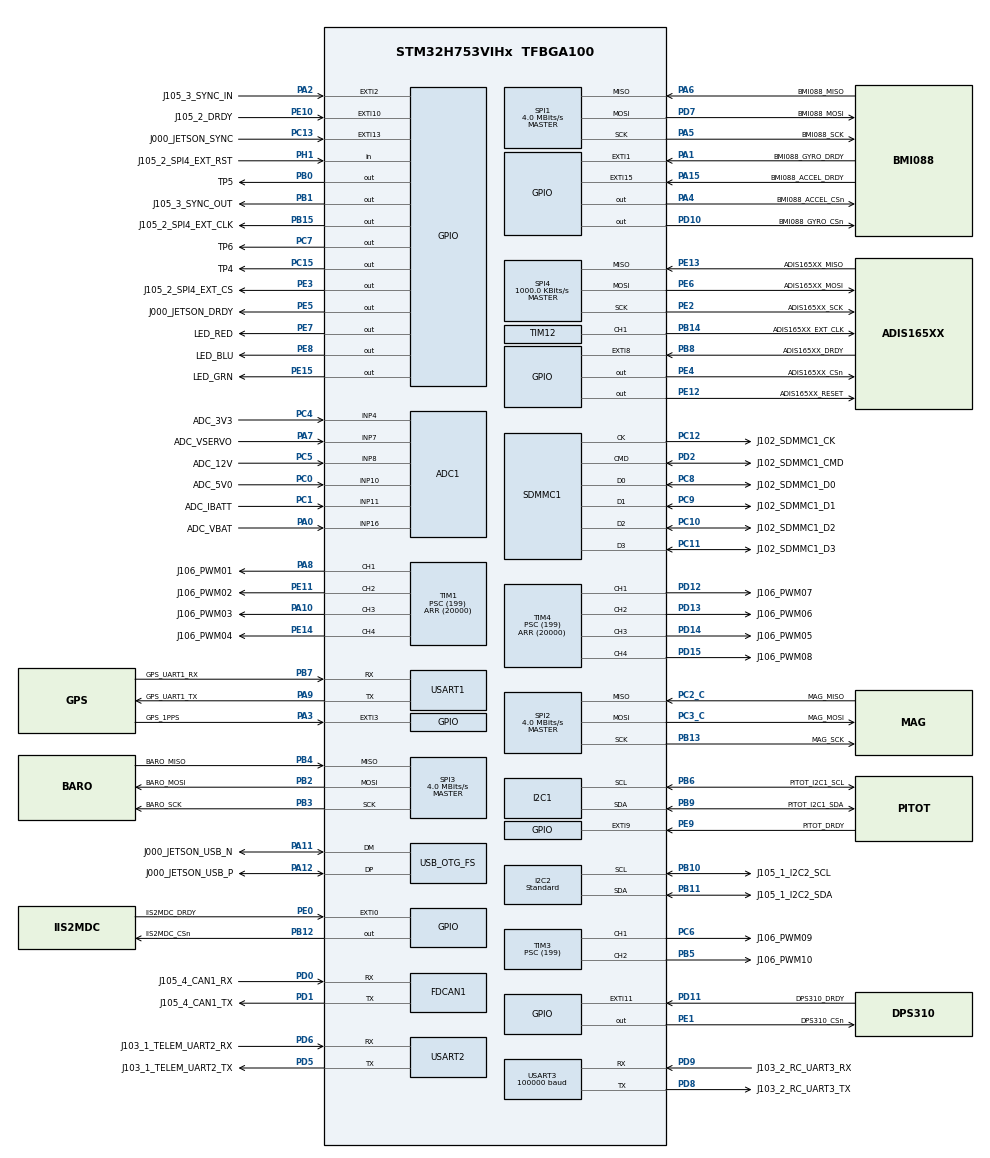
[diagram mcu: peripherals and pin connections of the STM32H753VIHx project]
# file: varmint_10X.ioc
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ADC1.Channel-0\#ChannelRegularConversion=ADC_CHANNEL_4
ADC1.Channel-1\#ChannelRegularConversion=ADC_CHANNEL_7
ADC1.Channel-2\#ChannelRegularConversion=ADC_CHANNEL_8
ADC1.Channel-3\#ChannelRegularConversion=ADC_CHANNEL_10
ADC1.Channel-4\#ChannelRegularConversion=ADC_CHANNEL_11
ADC1.Channel-5\#ChannelRegularConversion=ADC_CHANNEL_16
ADC1.ClockPrescaler=ADC_CLOCK_ASYNC_DIV32
ADC1.ClockPrescalerADC3=ADC_CLOCK_ASYNC_DIV256
ADC1.ContinuousConvMode=DISABLE
ADC1.ConversionDataManagement=ADC_CONVERSIONDATA_DMA_ONESHOT
ADC1.EOCSelection=ADC_EOC_SEQ_CONV
ADC1.EnableAnalogWatchDog2=false
ADC1.LeftBitShift=ADC_LEFTBITSHIFT_NONE
ADC1.NbrOfConversion=6
ADC1.NbrOfConversionFlag=1
ADC1.OffsetNumber-0\#ChannelRegularConversion=ADC_OFFSET_NONE
ADC1.OffsetNumber-1\#ChannelRegularConversion=ADC_OFFSET_NONE
ADC1.OffsetNumber-2\#ChannelRegularConversion=ADC_OFFSET_NONE
ADC1.OffsetNumber-3\#ChannelRegularConversion=ADC_OFFSET_NONE
ADC1.OffsetNumber-4\#ChannelRegularConversion=ADC_OFFSET_NONE
ADC1.OffsetNumber-5\#ChannelRegularConversion=ADC_OFFSET_NONE
ADC1.OffsetSignedSaturation-0\#ChannelRegularConversion=DISABLE
ADC1.OffsetSignedSaturation-1\#ChannelRegularConversion=DISABLE
ADC1.OffsetSignedSaturation-2\#ChannelRegularConversion=DISABLE
ADC1.OffsetSignedSaturation-3\#ChannelRegularConversion=DISABLE
ADC1.OffsetSignedSaturation-4\#ChannelRegularConversion=DISABLE
ADC1.OffsetSignedSaturation-5\#ChannelRegularConversion=DISABLE
ADC1.OversamplingMode=DISABLE
ADC1.Rank-0\#ChannelRegularConversion=1
ADC1.Rank-1\#ChannelRegularConversion=2
ADC1.Rank-2\#ChannelRegularConversion=3
ADC1.Rank-3\#ChannelRegularConversion=4
ADC1.Rank-4\#ChannelRegularConversion=5
ADC1.Rank-5\#ChannelRegularConversion=6
ADC1.SamplingTime-0\#ChannelRegularConversion=ADC_SAMPLETIME_810CYCLES_5
ADC1.SamplingTime-1\#ChannelRegularConversion=ADC_SAMPLETIME_810CYCLES_5
ADC1.SamplingTime-2\#ChannelRegularConversion=ADC_SAMPLETIME_810CYCLES_5
ADC1.SamplingTime-3\#ChannelRegularConversion=ADC_SAMPLETIME_810CYCLES_5
ADC1.SamplingTime-4\#ChannelRegularConversion=ADC_SAMPLETIME_810CYCLES_5
ADC1.SamplingTime-5\#ChannelRegularConversion=ADC_SAMPLETIME_810CYCLES_5
ADC1.master=1
ADC3.Channel-0\#ChannelRegularConversion=ADC_CHANNEL_TEMPSENSOR
ADC3.Channel-1\#ChannelRegularConversion=ADC_CHANNEL_VBAT
ADC3.Channel-2\#ChannelRegularConversion=ADC_CHANNEL_VREFINT
ADC3.ClockPrescaler=ADC_CLOCK_ASYNC_DIV32
ADC3.ClockPrescalerADC3=ADC_CLOCK_ASYNC_DIV256
ADC3.ContinuousConvMode=DISABLE
ADC3.ConversionDataManagement=ADC_CONVERSIONDATA_DMA_ONESHOT
ADC3.EOCSelection=ADC_EOC_SEQ_CONV
ADC3.NbrOfConversion=3
ADC3.NbrOfConversionFlag=1
ADC3.OffsetNumber-0\#ChannelRegularConversion=ADC_OFFSET_NONE
ADC3.OffsetNumber-1\#ChannelRegularConversion=ADC_OFFSET_NONE
ADC3.OffsetNumber-2\#ChannelRegularConversion=ADC_OFFSET_NONE
ADC3.OffsetSignedSaturation-0\#ChannelRegularConversion=DISABLE
ADC3.OffsetSignedSaturation-1\#ChannelRegularConversion=DISABLE
ADC3.OffsetSignedSaturation-2\#ChannelRegularConversion=DISABLE
ADC3.Rank-0\#ChannelRegularConversion=1
ADC3.Rank-1\#ChannelRegularConversion=2
ADC3.Rank-2\#ChannelRegularConversion=3
ADC3.SamplingTime-0\#ChannelRegularConversion=ADC_SAMPLETIME_810CYCLES_5
ADC3.SamplingTime-1\#ChannelRegularConversion=ADC_SAMPLETIME_810CYCLES_5
ADC3.SamplingTime-2\#ChannelRegularConversion=ADC_SAMPLETIME_810CYCLES_5
Bdma.ADC3.0.Direction=DMA_PERIPH_TO_MEMORY
Bdma.ADC3.0.EventEnable=DISABLE
Bdma.ADC3.0.Instance=BDMA_Channel0
Bdma.ADC3.0.MemDataAlignment=DMA_MDATAALIGN_WORD
Bdma.ADC3.0.MemInc=DMA_MINC_ENABLE
Bdma.ADC3.0.Mode=DMA_NORMAL
Bdma.ADC3.0.PeriphDataAlignment=DMA_PDATAALIGN_WORD
Bdma.ADC3.0.PeriphInc=DMA_PINC_DISABLE
Bdma.ADC3.0.Polarity=HAL_DMAMUX_REQ_GEN_RISING
Bdma.ADC3.0.Priority=DMA_PRIORITY_LOW
Bdma.ADC3.0.RequestNumber=1
Bdma.ADC3.0.SignalID=NONE
Bdma.ADC3.0.SyncEnable=DISABLE
Bdma.ADC3.0.SyncPolarity=HAL_DMAMUX_SYNC_NO_EVENT
Bdma.ADC3.0.SyncRequestNumber=1
Bdma.ADC3.0.SyncSignalID=NONE
Bdma.Request0=ADC3
Bdma.RequestsNb=1
CORTEX_M7.AccessPermission-Cortex_Memory_Protection_Unit_Region0_Settings=MPU_REGION_FULL_ACCESS
CORTEX_M7.AccessPermission-Cortex_Memory_Protection_Unit_Region1_Settings=MPU_REGION_FULL_ACCESS
CORTEX_M7.BaseAddress-Cortex_Memory_Protection_Unit_Region0_Settings=0x30040000
CORTEX_M7.BaseAddress-Cortex_Memory_Protection_Unit_Region1_Settings=0x38000000
CORTEX_M7.CPU_DCache=Enabled
CORTEX_M7.CPU_ICache=Enabled
CORTEX_M7.DisableExec-Cortex_Memory_Protection_Unit_Region0_Settings=MPU_INSTRUCTION_ACCESS_ENABLE
CORTEX_M7.Enable-Cortex_Memory_Protection_Unit_Region0_Settings=MPU_REGION_ENABLE
CORTEX_M7.Enable-Cortex_Memory_Protection_Unit_Region1_Settings=MPU_REGION_ENABLE
CORTEX_M7.IsCacheable-Cortex_Memory_Protection_Unit_Region0_Settings=MPU_ACCESS_CACHEABLE
CORTEX_M7.IsCacheable-Cortex_Memory_Protection_Unit_Region1_Settings=MPU_ACCESS_CACHEABLE
CORTEX_M7.IsShareable-Cortex_Memory_Protection_Unit_Region0_Settings=MPU_ACCESS_SHAREABLE
CORTEX_M7.IsShareable-Cortex_Memory_Protection_Unit_Region1_Settings=MPU_ACCESS_SHAREABLE
CORTEX_M7.MPU_Control=MPU_PRIVILEGED_DEFAULT
CORTEX_M7.Size-Cortex_Memory_Protection_Unit_Region0_Settings=MPU_REGION_SIZE_32KB
CORTEX_M7.Size-Cortex_Memory_Protection_Unit_Region1_Settings=MPU_REGION_SIZE_64KB
CORTEX_M7.SubRegionDisable-Cortex_Memory_Protection_Unit_Region0_Settings=0x00
CORTEX_M7.default_mode_Activation=0
Dma.ADC1.12.Direction=DMA_PERIPH_TO_MEMORY
Dma.ADC1.12.EventEnable=DISABLE
Dma.ADC1.12.FIFOMode=DMA_FIFOMODE_ENABLE
Dma.ADC1.12.FIFOThreshold=DMA_FIFO_THRESHOLD_FULL
Dma.ADC1.12.Instance=DMA2_Stream0
Dma.ADC1.12.MemBurst=DMA_MBURST_SINGLE
Dma.ADC1.12.MemDataAlignment=DMA_MDATAALIGN_WORD
Dma.ADC1.12.MemInc=DMA_MINC_ENABLE
Dma.ADC1.12.Mode=DMA_NORMAL
Dma.ADC1.12.PeriphBurst=DMA_PBURST_SINGLE
Dma.ADC1.12.PeriphDataAlignment=DMA_PDATAALIGN_WORD
Dma.ADC1.12.PeriphInc=DMA_PINC_DISABLE
Dma.ADC1.12.Polarity=HAL_DMAMUX_REQ_GEN_RISING
Dma.ADC1.12.Priority=DMA_PRIORITY_LOW
Dma.ADC1.12.RequestNumber=1
Dma.ADC1.12.SignalID=NONE
Dma.ADC1.12.SyncEnable=DISABLE
Dma.ADC1.12.SyncPolarity=HAL_DMAMUX_SYNC_NO_EVENT
Dma.ADC1.12.SyncRequestNumber=1
Dma.ADC1.12.SyncSignalID=NONE
Dma.I2C1_RX.10.Direction=DMA_PERIPH_TO_MEMORY
Dma.I2C1_RX.10.EventEnable=DISABLE
Dma.I2C1_RX.10.FIFOMode=DMA_FIFOMODE_ENABLE
Dma.I2C1_RX.10.FIFOThreshold=DMA_FIFO_THRESHOLD_FULL
Dma.I2C1_RX.10.Instance=DMA1_Stream0
Dma.I2C1_RX.10.MemBurst=DMA_MBURST_SINGLE
Dma.I2C1_RX.10.MemDataAlignment=DMA_MDATAALIGN_BYTE
Dma.I2C1_RX.10.MemInc=DMA_MINC_ENABLE
Dma.I2C1_RX.10.Mode=DMA_NORMAL
Dma.I2C1_RX.10.PeriphBurst=DMA_PBURST_SINGLE
Dma.I2C1_RX.10.PeriphDataAlignment=DMA_PDATAALIGN_BYTE
Dma.I2C1_RX.10.PeriphInc=DMA_PINC_DISABLE
Dma.I2C1_RX.10.Polarity=HAL_DMAMUX_REQ_GEN_RISING
Dma.I2C1_RX.10.Priority=DMA_PRIORITY_LOW
Dma.I2C1_RX.10.RequestNumber=1
Dma.I2C1_RX.10.SignalID=NONE
Dma.I2C1_RX.10.SyncEnable=DISABLE
Dma.I2C1_RX.10.SyncPolarity=HAL_DMAMUX_SYNC_NO_EVENT
Dma.I2C1_RX.10.SyncRequestNumber=1
Dma.I2C1_RX.10.SyncSignalID=NONE
Dma.I2C1_TX.11.Direction=DMA_MEMORY_TO_PERIPH
Dma.I2C1_TX.11.EventEnable=DISABLE
Dma.I2C1_TX.11.FIFOMode=DMA_FIFOMODE_ENABLE
Dma.I2C1_TX.11.FIFOThreshold=DMA_FIFO_THRESHOLD_FULL
Dma.I2C1_TX.11.Instance=DMA1_Stream1
Dma.I2C1_TX.11.MemBurst=DMA_MBURST_SINGLE
Dma.I2C1_TX.11.MemDataAlignment=DMA_MDATAALIGN_BYTE
Dma.I2C1_TX.11.MemInc=DMA_MINC_ENABLE
Dma.I2C1_TX.11.Mode=DMA_NORMAL
Dma.I2C1_TX.11.PeriphBurst=DMA_PBURST_SINGLE
Dma.I2C1_TX.11.PeriphDataAlignment=DMA_PDATAALIGN_BYTE
Dma.I2C1_TX.11.PeriphInc=DMA_PINC_DISABLE
Dma.I2C1_TX.11.Polarity=HAL_DMAMUX_REQ_GEN_RISING
Dma.I2C1_TX.11.Priority=DMA_PRIORITY_LOW
Dma.I2C1_TX.11.RequestNumber=1
Dma.I2C1_TX.11.SignalID=NONE
Dma.I2C1_TX.11.SyncEnable=DISABLE
Dma.I2C1_TX.11.SyncPolarity=HAL_DMAMUX_SYNC_NO_EVENT
Dma.I2C1_TX.11.SyncRequestNumber=1
Dma.I2C1_TX.11.SyncSignalID=NONE
Dma.I2C2_RX.14.Direction=DMA_PERIPH_TO_MEMORY
Dma.I2C2_RX.14.EventEnable=DISABLE
Dma.I2C2_RX.14.FIFOMode=DMA_FIFOMODE_ENABLE
Dma.I2C2_RX.14.FIFOThreshold=DMA_FIFO_THRESHOLD_FULL
Dma.I2C2_RX.14.Instance=DMA2_Stream6
Dma.I2C2_RX.14.MemBurst=DMA_MBURST_SINGLE
Dma.I2C2_RX.14.MemDataAlignment=DMA_MDATAALIGN_BYTE
Dma.I2C2_RX.14.MemInc=DMA_MINC_ENABLE
Dma.I2C2_RX.14.Mode=DMA_NORMAL
Dma.I2C2_RX.14.PeriphBurst=DMA_PBURST_SINGLE
Dma.I2C2_RX.14.PeriphDataAlignment=DMA_PDATAALIGN_BYTE
Dma.I2C2_RX.14.PeriphInc=DMA_PINC_DISABLE
Dma.I2C2_RX.14.Polarity=HAL_DMAMUX_REQ_GEN_RISING
Dma.I2C2_RX.14.Priority=DMA_PRIORITY_LOW
Dma.I2C2_RX.14.RequestNumber=1
Dma.I2C2_RX.14.SignalID=NONE
Dma.I2C2_RX.14.SyncEnable=DISABLE
Dma.I2C2_RX.14.SyncPolarity=HAL_DMAMUX_SYNC_NO_EVENT
Dma.I2C2_RX.14.SyncRequestNumber=1
Dma.I2C2_RX.14.SyncSignalID=NONE
Dma.I2C2_TX.15.Direction=DMA_MEMORY_TO_PERIPH
Dma.I2C2_TX.15.EventEnable=DISABLE
Dma.I2C2_TX.15.FIFOMode=DMA_FIFOMODE_ENABLE
Dma.I2C2_TX.15.FIFOThreshold=DMA_FIFO_THRESHOLD_FULL
Dma.I2C2_TX.15.Instance=DMA2_Stream7
Dma.I2C2_TX.15.MemBurst=DMA_MBURST_SINGLE
Dma.I2C2_TX.15.MemDataAlignment=DMA_MDATAALIGN_BYTE
Dma.I2C2_TX.15.MemInc=DMA_MINC_ENABLE
Dma.I2C2_TX.15.Mode=DMA_NORMAL
Dma.I2C2_TX.15.PeriphBurst=DMA_PBURST_SINGLE
Dma.I2C2_TX.15.PeriphDataAlignment=DMA_PDATAALIGN_BYTE
Dma.I2C2_TX.15.PeriphInc=DMA_PINC_DISABLE
Dma.I2C2_TX.15.Polarity=HAL_DMAMUX_REQ_GEN_RISING
Dma.I2C2_TX.15.Priority=DMA_PRIORITY_LOW
Dma.I2C2_TX.15.RequestNumber=1
Dma.I2C2_TX.15.SignalID=NONE
Dma.I2C2_TX.15.SyncEnable=DISABLE
Dma.I2C2_TX.15.SyncPolarity=HAL_DMAMUX_SYNC_NO_EVENT
Dma.I2C2_TX.15.SyncRequestNumber=1
Dma.I2C2_TX.15.SyncSignalID=NONE
Dma.Request0=SPI1_RX
Dma.Request1=SPI1_TX
Dma.Request10=I2C1_RX
Dma.Request11=I2C1_TX
Dma.Request12=ADC1
Dma.Request13=USART1_RX
Dma.Request14=I2C2_RX
Dma.Request15=I2C2_TX
Dma.Request2=SPI4_RX
Dma.Request3=SPI4_TX
Dma.Request4=SPI3_RX
Dma.Request5=SPI3_TX
Dma.Request6=SPI2_RX
Dma.Request7=SPI2_TX
Dma.Request8=USART3_RX
Dma.Request9=USART2_TX
Dma.SPI1_RX.0.Direction=DMA_PERIPH_TO_MEMORY
Dma.SPI1_RX.0.EventEnable=DISABLE
Dma.SPI1_RX.0.FIFOMode=DMA_FIFOMODE_ENABLE
Dma.SPI1_RX.0.FIFOThreshold=DMA_FIFO_THRESHOLD_FULL
Dma.SPI1_RX.0.Instance=DMA1_Stream4
Dma.SPI1_RX.0.MemBurst=DMA_MBURST_SINGLE
Dma.SPI1_RX.0.MemDataAlignment=DMA_MDATAALIGN_BYTE
Dma.SPI1_RX.0.MemInc=DMA_MINC_ENABLE
Dma.SPI1_RX.0.Mode=DMA_NORMAL
Dma.SPI1_RX.0.PeriphBurst=DMA_PBURST_SINGLE
Dma.SPI1_RX.0.PeriphDataAlignment=DMA_PDATAALIGN_BYTE
Dma.SPI1_RX.0.PeriphInc=DMA_PINC_DISABLE
Dma.SPI1_RX.0.Polarity=HAL_DMAMUX_REQ_GEN_RISING
Dma.SPI1_RX.0.Priority=DMA_PRIORITY_LOW
Dma.SPI1_RX.0.RequestNumber=1
Dma.SPI1_RX.0.SignalID=NONE
Dma.SPI1_RX.0.SyncEnable=DISABLE
Dma.SPI1_RX.0.SyncPolarity=HAL_DMAMUX_SYNC_NO_EVENT
Dma.SPI1_RX.0.SyncRequestNumber=1
Dma.SPI1_RX.0.SyncSignalID=NONE
Dma.SPI1_TX.1.Direction=DMA_MEMORY_TO_PERIPH
Dma.SPI1_TX.1.EventEnable=DISABLE
Dma.SPI1_TX.1.FIFOMode=DMA_FIFOMODE_ENABLE
Dma.SPI1_TX.1.FIFOThreshold=DMA_FIFO_THRESHOLD_FULL
Dma.SPI1_TX.1.Instance=DMA1_Stream5
Dma.SPI1_TX.1.MemBurst=DMA_MBURST_SINGLE
Dma.SPI1_TX.1.MemDataAlignment=DMA_MDATAALIGN_BYTE
Dma.SPI1_TX.1.MemInc=DMA_MINC_ENABLE
Dma.SPI1_TX.1.Mode=DMA_NORMAL
Dma.SPI1_TX.1.PeriphBurst=DMA_PBURST_SINGLE
Dma.SPI1_TX.1.PeriphDataAlignment=DMA_PDATAALIGN_BYTE
Dma.SPI1_TX.1.PeriphInc=DMA_PINC_DISABLE
Dma.SPI1_TX.1.Polarity=HAL_DMAMUX_REQ_GEN_RISING
Dma.SPI1_TX.1.Priority=DMA_PRIORITY_LOW
Dma.SPI1_TX.1.RequestNumber=1
Dma.SPI1_TX.1.SignalID=NONE
Dma.SPI1_TX.1.SyncEnable=DISABLE
Dma.SPI1_TX.1.SyncPolarity=HAL_DMAMUX_SYNC_NO_EVENT
Dma.SPI1_TX.1.SyncRequestNumber=1
Dma.SPI1_TX.1.SyncSignalID=NONE
Dma.SPI2_RX.6.Direction=DMA_PERIPH_TO_MEMORY
Dma.SPI2_RX.6.EventEnable=DISABLE
Dma.SPI2_RX.6.FIFOMode=DMA_FIFOMODE_ENABLE
Dma.SPI2_RX.6.FIFOThreshold=DMA_FIFO_THRESHOLD_FULL
Dma.SPI2_RX.6.Instance=DMA1_Stream2
Dma.SPI2_RX.6.MemBurst=DMA_MBURST_SINGLE
Dma.SPI2_RX.6.MemDataAlignment=DMA_MDATAALIGN_BYTE
Dma.SPI2_RX.6.MemInc=DMA_MINC_ENABLE
Dma.SPI2_RX.6.Mode=DMA_NORMAL
Dma.SPI2_RX.6.PeriphBurst=DMA_PBURST_SINGLE
Dma.SPI2_RX.6.PeriphDataAlignment=DMA_PDATAALIGN_BYTE
Dma.SPI2_RX.6.PeriphInc=DMA_PINC_DISABLE
Dma.SPI2_RX.6.Polarity=HAL_DMAMUX_REQ_GEN_RISING
Dma.SPI2_RX.6.Priority=DMA_PRIORITY_LOW
Dma.SPI2_RX.6.RequestNumber=1
Dma.SPI2_RX.6.SignalID=NONE
Dma.SPI2_RX.6.SyncEnable=DISABLE
Dma.SPI2_RX.6.SyncPolarity=HAL_DMAMUX_SYNC_NO_EVENT
Dma.SPI2_RX.6.SyncRequestNumber=1
Dma.SPI2_RX.6.SyncSignalID=NONE
Dma.SPI2_TX.7.Direction=DMA_MEMORY_TO_PERIPH
Dma.SPI2_TX.7.EventEnable=DISABLE
Dma.SPI2_TX.7.FIFOMode=DMA_FIFOMODE_ENABLE
Dma.SPI2_TX.7.FIFOThreshold=DMA_FIFO_THRESHOLD_FULL
Dma.SPI2_TX.7.Instance=DMA1_Stream3
Dma.SPI2_TX.7.MemBurst=DMA_MBURST_SINGLE
Dma.SPI2_TX.7.MemDataAlignment=DMA_MDATAALIGN_BYTE
Dma.SPI2_TX.7.MemInc=DMA_MINC_ENABLE
Dma.SPI2_TX.7.Mode=DMA_NORMAL
Dma.SPI2_TX.7.PeriphBurst=DMA_PBURST_SINGLE
Dma.SPI2_TX.7.PeriphDataAlignment=DMA_PDATAALIGN_BYTE
Dma.SPI2_TX.7.PeriphInc=DMA_PINC_DISABLE
Dma.SPI2_TX.7.Polarity=HAL_DMAMUX_REQ_GEN_RISING
Dma.SPI2_TX.7.Priority=DMA_PRIORITY_LOW
Dma.SPI2_TX.7.RequestNumber=1
Dma.SPI2_TX.7.SignalID=NONE
Dma.SPI2_TX.7.SyncEnable=DISABLE
Dma.SPI2_TX.7.SyncPolarity=HAL_DMAMUX_SYNC_NO_EVENT
Dma.SPI2_TX.7.SyncRequestNumber=1
Dma.SPI2_TX.7.SyncSignalID=NONE
Dma.SPI3_RX.4.Direction=DMA_PERIPH_TO_MEMORY
Dma.SPI3_RX.4.EventEnable=DISABLE
Dma.SPI3_RX.4.FIFOMode=DMA_FIFOMODE_ENABLE
Dma.SPI3_RX.4.FIFOThreshold=DMA_FIFO_THRESHOLD_FULL
Dma.SPI3_RX.4.Instance=DMA1_Stream6
Dma.SPI3_RX.4.MemBurst=DMA_MBURST_SINGLE
Dma.SPI3_RX.4.MemDataAlignment=DMA_MDATAALIGN_BYTE
Dma.SPI3_RX.4.MemInc=DMA_MINC_ENABLE
Dma.SPI3_RX.4.Mode=DMA_NORMAL
Dma.SPI3_RX.4.PeriphBurst=DMA_PBURST_SINGLE
Dma.SPI3_RX.4.PeriphDataAlignment=DMA_PDATAALIGN_BYTE
Dma.SPI3_RX.4.PeriphInc=DMA_PINC_DISABLE
Dma.SPI3_RX.4.Polarity=HAL_DMAMUX_REQ_GEN_RISING
Dma.SPI3_RX.4.Priority=DMA_PRIORITY_LOW
Dma.SPI3_RX.4.RequestNumber=1
Dma.SPI3_RX.4.SignalID=NONE
Dma.SPI3_RX.4.SyncEnable=DISABLE
Dma.SPI3_RX.4.SyncPolarity=HAL_DMAMUX_SYNC_NO_EVENT
Dma.SPI3_RX.4.SyncRequestNumber=1
Dma.SPI3_RX.4.SyncSignalID=NONE
Dma.SPI3_TX.5.Direction=DMA_MEMORY_TO_PERIPH
Dma.SPI3_TX.5.EventEnable=DISABLE
Dma.SPI3_TX.5.FIFOMode=DMA_FIFOMODE_ENABLE
Dma.SPI3_TX.5.FIFOThreshold=DMA_FIFO_THRESHOLD_FULL
Dma.SPI3_TX.5.Instance=DMA1_Stream7
Dma.SPI3_TX.5.MemBurst=DMA_MBURST_SINGLE
Dma.SPI3_TX.5.MemDataAlignment=DMA_MDATAALIGN_BYTE
Dma.SPI3_TX.5.MemInc=DMA_MINC_ENABLE
Dma.SPI3_TX.5.Mode=DMA_NORMAL
Dma.SPI3_TX.5.PeriphBurst=DMA_PBURST_SINGLE
Dma.SPI3_TX.5.PeriphDataAlignment=DMA_PDATAALIGN_BYTE
Dma.SPI3_TX.5.PeriphInc=DMA_PINC_DISABLE
Dma.SPI3_TX.5.Polarity=HAL_DMAMUX_REQ_GEN_RISING
Dma.SPI3_TX.5.Priority=DMA_PRIORITY_LOW
Dma.SPI3_TX.5.RequestNumber=1
Dma.SPI3_TX.5.SignalID=NONE
Dma.SPI3_TX.5.SyncEnable=DISABLE
Dma.SPI3_TX.5.SyncPolarity=HAL_DMAMUX_SYNC_NO_EVENT
Dma.SPI3_TX.5.SyncRequestNumber=1
Dma.SPI3_TX.5.SyncSignalID=NONE
Dma.SPI4_RX.2.Direction=DMA_PERIPH_TO_MEMORY
Dma.SPI4_RX.2.EventEnable=DISABLE
Dma.SPI4_RX.2.FIFOMode=DMA_FIFOMODE_ENABLE
Dma.SPI4_RX.2.FIFOThreshold=DMA_FIFO_THRESHOLD_FULL
Dma.SPI4_RX.2.Instance=DMA2_Stream2
Dma.SPI4_RX.2.MemBurst=DMA_MBURST_SINGLE
Dma.SPI4_RX.2.MemDataAlignment=DMA_MDATAALIGN_BYTE
Dma.SPI4_RX.2.MemInc=DMA_MINC_ENABLE
Dma.SPI4_RX.2.Mode=DMA_NORMAL
Dma.SPI4_RX.2.PeriphBurst=DMA_PBURST_SINGLE
Dma.SPI4_RX.2.PeriphDataAlignment=DMA_PDATAALIGN_BYTE
Dma.SPI4_RX.2.PeriphInc=DMA_PINC_DISABLE
Dma.SPI4_RX.2.Polarity=HAL_DMAMUX_REQ_GEN_RISING
Dma.SPI4_RX.2.Priority=DMA_PRIORITY_LOW
Dma.SPI4_RX.2.RequestNumber=1
Dma.SPI4_RX.2.SignalID=NONE
Dma.SPI4_RX.2.SyncEnable=DISABLE
Dma.SPI4_RX.2.SyncPolarity=HAL_DMAMUX_SYNC_NO_EVENT
Dma.SPI4_RX.2.SyncRequestNumber=1
Dma.SPI4_RX.2.SyncSignalID=NONE
Dma.SPI4_TX.3.Direction=DMA_MEMORY_TO_PERIPH
Dma.SPI4_TX.3.EventEnable=DISABLE
Dma.SPI4_TX.3.FIFOMode=DMA_FIFOMODE_ENABLE
Dma.SPI4_TX.3.FIFOThreshold=DMA_FIFO_THRESHOLD_FULL
Dma.SPI4_TX.3.Instance=DMA2_Stream3
Dma.SPI4_TX.3.MemBurst=DMA_MBURST_SINGLE
Dma.SPI4_TX.3.MemDataAlignment=DMA_MDATAALIGN_BYTE
Dma.SPI4_TX.3.MemInc=DMA_MINC_ENABLE
Dma.SPI4_TX.3.Mode=DMA_NORMAL
Dma.SPI4_TX.3.PeriphBurst=DMA_PBURST_SINGLE
Dma.SPI4_TX.3.PeriphDataAlignment=DMA_PDATAALIGN_BYTE
Dma.SPI4_TX.3.PeriphInc=DMA_PINC_DISABLE
Dma.SPI4_TX.3.Polarity=HAL_DMAMUX_REQ_GEN_RISING
Dma.SPI4_TX.3.Priority=DMA_PRIORITY_LOW
Dma.SPI4_TX.3.RequestNumber=1
Dma.SPI4_TX.3.SignalID=NONE
Dma.SPI4_TX.3.SyncEnable=DISABLE
Dma.SPI4_TX.3.SyncPolarity=HAL_DMAMUX_SYNC_NO_EVENT
Dma.SPI4_TX.3.SyncRequestNumber=1
Dma.SPI4_TX.3.SyncSignalID=NONE
Dma.USART1_RX.13.Direction=DMA_PERIPH_TO_MEMORY
Dma.USART1_RX.13.EventEnable=DISABLE
Dma.USART1_RX.13.FIFOMode=DMA_FIFOMODE_DISABLE
Dma.USART1_RX.13.Instance=DMA2_Stream4
Dma.USART1_RX.13.MemDataAlignment=DMA_MDATAALIGN_BYTE
Dma.USART1_RX.13.MemInc=DMA_MINC_ENABLE
Dma.USART1_RX.13.Mode=DMA_NORMAL
Dma.USART1_RX.13.PeriphDataAlignment=DMA_PDATAALIGN_BYTE
Dma.USART1_RX.13.PeriphInc=DMA_PINC_DISABLE
Dma.USART1_RX.13.Polarity=HAL_DMAMUX_REQ_GEN_RISING
Dma.USART1_RX.13.Priority=DMA_PRIORITY_LOW
Dma.USART1_RX.13.RequestNumber=1
Dma.USART1_RX.13.SignalID=NONE
Dma.USART1_RX.13.SyncEnable=DISABLE
Dma.USART1_RX.13.SyncPolarity=HAL_DMAMUX_SYNC_NO_EVENT
Dma.USART1_RX.13.SyncRequestNumber=1
Dma.USART1_RX.13.SyncSignalID=NONE
Dma.USART2_TX.9.Direction=DMA_MEMORY_TO_PERIPH
Dma.USART2_TX.9.EventEnable=DISABLE
Dma.USART2_TX.9.FIFOMode=DMA_FIFOMODE_ENABLE
Dma.USART2_TX.9.FIFOThreshold=DMA_FIFO_THRESHOLD_FULL
Dma.USART2_TX.9.Instance=DMA2_Stream5
Dma.USART2_TX.9.MemBurst=DMA_MBURST_SINGLE
Dma.USART2_TX.9.MemDataAlignment=DMA_MDATAALIGN_BYTE
Dma.USART2_TX.9.MemInc=DMA_MINC_ENABLE
Dma.USART2_TX.9.Mode=DMA_NORMAL
Dma.USART2_TX.9.PeriphBurst=DMA_PBURST_SINGLE
Dma.USART2_TX.9.PeriphDataAlignment=DMA_PDATAALIGN_BYTE
Dma.USART2_TX.9.PeriphInc=DMA_PINC_DISABLE
Dma.USART2_TX.9.Polarity=HAL_DMAMUX_REQ_GEN_RISING
Dma.USART2_TX.9.Priority=DMA_PRIORITY_LOW
Dma.USART2_TX.9.RequestNumber=1
Dma.USART2_TX.9.SignalID=NONE
Dma.USART2_TX.9.SyncEnable=DISABLE
Dma.USART2_TX.9.SyncPolarity=HAL_DMAMUX_SYNC_NO_EVENT
Dma.USART2_TX.9.SyncRequestNumber=1
Dma.USART2_TX.9.SyncSignalID=NONE
Dma.USART3_RX.8.Direction=DMA_PERIPH_TO_MEMORY
Dma.USART3_RX.8.EventEnable=DISABLE
Dma.USART3_RX.8.FIFOMode=DMA_FIFOMODE_ENABLE
Dma.USART3_RX.8.FIFOThreshold=DMA_FIFO_THRESHOLD_FULL
Dma.USART3_RX.8.Instance=DMA2_Stream1
Dma.USART3_RX.8.MemBurst=DMA_MBURST_SINGLE
Dma.USART3_RX.8.MemDataAlignment=DMA_MDATAALIGN_BYTE
Dma.USART3_RX.8.MemInc=DMA_MINC_ENABLE
Dma.USART3_RX.8.Mode=DMA_NORMAL
Dma.USART3_RX.8.PeriphBurst=DMA_PBURST_SINGLE
Dma.USART3_RX.8.PeriphDataAlignment=DMA_PDATAALIGN_BYTE
Dma.USART3_RX.8.PeriphInc=DMA_PINC_DISABLE
Dma.USART3_RX.8.Polarity=HAL_DMAMUX_REQ_GEN_RISING
Dma.USART3_RX.8.Priority=DMA_PRIORITY_LOW
Dma.USART3_RX.8.RequestNumber=1
Dma.USART3_RX.8.SignalID=NONE
Dma.USART3_RX.8.SyncEnable=DISABLE
Dma.USART3_RX.8.SyncPolarity=HAL_DMAMUX_SYNC_NO_EVENT
Dma.USART3_RX.8.SyncRequestNumber=1
Dma.USART3_RX.8.SyncSignalID=NONE
FDCAN1.CalculateBaudRateNominal=200000
FDCAN1.CalculateTimeBitNominal=5000
FDCAN1.CalculateTimeQuantumNominal=1000.0
I2C1.Timing=0x10C0ECFF
I2C2.I2C_Speed_Mode=I2C_Standard
I2C2.Timing=0x10C0ECFF
Mcu.Family=STM32H7
Mcu.Name=STM32H753VIHx
Mcu.Package=TFBGA100
NVIC.ADC3_IRQn=true\:5\:0\:true\:false\:true\:true\:true\:true
NVIC.ADC_IRQn=true\:5\:0\:true\:false\:true\:true\:true\:true
NVIC.BDMA_Channel0_IRQn=true\:5\:0\:true\:false\:true\:false\:true\:true
NVIC.DMA1_Stream0_IRQn=true\:5\:0\:true\:false\:true\:false\:true\:true
NVIC.DMA1_Stream1_IRQn=true\:5\:0\:true\:false\:true\:false\:true\:true
NVIC.DMA1_Stream2_IRQn=true\:5\:0\:true\:false\:true\:false\:true\:true
NVIC.DMA1_Stream3_IRQn=true\:5\:0\:true\:false\:true\:false\:true\:true
NVIC.DMA1_Stream4_IRQn=true\:5\:0\:true\:false\:true\:false\:true\:true
NVIC.DMA1_Stream5_IRQn=true\:5\:0\:true\:false\:true\:false\:true\:true
NVIC.DMA1_Stream6_IRQn=true\:5\:0\:true\:false\:true\:false\:true\:true
NVIC.DMA1_Stream7_IRQn=true\:5\:0\:true\:false\:true\:false\:true\:true
NVIC.DMA2_Stream0_IRQn=true\:5\:0\:true\:false\:true\:false\:true\:true
NVIC.DMA2_Stream1_IRQn=true\:5\:0\:true\:false\:true\:false\:true\:true
NVIC.DMA2_Stream2_IRQn=true\:5\:0\:true\:false\:true\:false\:true\:true
NVIC.DMA2_Stream3_IRQn=true\:5\:0\:true\:false\:true\:false\:true\:true
NVIC.DMA2_Stream4_IRQn=true\:5\:0\:true\:false\:true\:false\:true\:true
NVIC.DMA2_Stream5_IRQn=true\:5\:0\:true\:false\:true\:false\:true\:true
NVIC.DMA2_Stream6_IRQn=true\:5\:0\:true\:false\:true\:false\:true\:true
NVIC.DMA2_Stream7_IRQn=true\:5\:0\:true\:false\:true\:false\:true\:true
NVIC.EXTI0_IRQn=true\:5\:0\:true\:false\:true\:true\:true\:true
NVIC.EXTI15_10_IRQn=true\:5\:0\:true\:false\:true\:true\:true\:true
NVIC.EXTI1_IRQn=true\:5\:0\:true\:false\:true\:true\:true\:true
NVIC.EXTI2_IRQn=true\:5\:0\:true\:false\:true\:true\:true\:true
NVIC.EXTI3_IRQn=true\:5\:0\:true\:false\:true\:true\:true\:true
NVIC.EXTI9_5_IRQn=true\:5\:0\:true\:false\:true\:true\:true\:true
NVIC.I2C1_EV_IRQn=true\:5\:0\:true\:false\:true\:true\:true\:true
NVIC.I2C2_EV_IRQn=true\:5\:0\:true\:false\:true\:true\:true\:true
NVIC.OTG_FS_IRQn=true\:0\:0\:true\:false\:true\:true\:true\:true
NVIC.PriorityGroup=NVIC_PRIORITYGROUP_4
NVIC.RCC_IRQn=true\:0\:0\:true\:false\:true\:true\:false\:true
NVIC.SDMMC1_IRQn=true\:1\:0\:true\:false\:true\:true\:true\:true
NVIC.SPI1_IRQn=true\:5\:0\:true\:false\:true\:false\:true\:true
NVIC.SPI2_IRQn=true\:5\:0\:true\:false\:true\:true\:true\:true
NVIC.SPI3_IRQn=true\:5\:0\:true\:false\:true\:false\:true\:true
NVIC.SPI4_IRQn=true\:5\:0\:true\:false\:true\:false\:true\:true
NVIC.TIM17_IRQn=true\:5\:0\:true\:false\:true\:true\:true\:true
NVIC.TIM7_IRQn=true\:5\:0\:true\:false\:true\:true\:true\:true
NVIC.USART1_IRQn=true\:5\:0\:true\:false\:true\:true\:true\:true
NVIC.USART2_IRQn=true\:1\:0\:true\:false\:true\:true\:true\:true
NVIC.USART3_IRQn=true\:5\:0\:true\:false\:true\:true\:true\:true
PA0.GPIO_Label=ADC_VBAT
PA0.Mode=IN16-Single-Ended
PA0.Signal=ADC1_INP16
PA1.GPIO_Label=BMI088_GYRO_DRDY
PA1.GPIO_PuPd=GPIO_PULLDOWN
PA1.Signal=GPXTI1
PA10.GPIO_Label=J106_PWM03
PA10.Signal=S_TIM1_CH3
PA11.GPIO_Label=J000_JETSON_USB_N
PA11.Mode=Device_Only
PA11.Signal=USB_OTG_FS_DM
PA12.GPIO_Label=J000_JETSON_USB_P
PA12.Mode=Device_Only
PA12.Signal=USB_OTG_FS_DP
PA13\ (JTMS/SWDIO).GPIO_Label=J101_DEBUG_SWDIO
PA13\ (JTMS/SWDIO).Mode=Serial_Wire
PA13\ (JTMS/SWDIO).Signal=DEBUG_JTMS-SWDIO
PA14\ (JTCK/SWCLK).GPIO_Label=J101_DEBUG_SWCLK
PA14\ (JTCK/SWCLK).Mode=Serial_Wire
PA14\ (JTCK/SWCLK).Signal=DEBUG_JTCK-SWCLK
PA15\ (JTDI).GPIO_Label=BMI088_ACCEL_DRDY
PA15\ (JTDI).GPIO_PuPd=GPIO_PULLDOWN
PA15\ (JTDI).Signal=GPXTI15
PA2.GPIO_Label=J105_3_SYNC_IN
PA2.GPIO_PuPd=GPIO_PULLDOWN
PA2.Signal=GPXTI2
PA3.GPIO_Label=GPS_1PPS
PA3.GPIO_PuPd=GPIO_PULLDOWN
PA3.Signal=GPXTI3
PA4.GPIO_Label=BMI088_ACCEL_CSn
PA4.GPIO_PuPd=GPIO_NOPULL
PA4.PinState=GPIO_PIN_SET
PA4.Signal=GPIO_Output
PA5.GPIO_Label=BMI088_SCK
PA5.Mode=Full_Duplex_Master
PA5.Signal=SPI1_SCK
PA6.GPIO_Label=BMI088_MISO
PA6.Mode=Full_Duplex_Master
PA6.Signal=SPI1_MISO
PA7.GPIO_Label=ADC_VSERVO
PA7.Signal=ADCx_INP7
PA8.GPIO_Label=J106_PWM01
PA8.Signal=S_TIM1_CH1
PA9.GPIO_Label=GPS_UART1_TX
PA9.Mode=Asynchronous
PA9.Signal=USART1_TX
PB0.GPIO_Label=TP5
PB0.GPIO_PuPd=GPIO_NOPULL
PB0.Signal=GPIO_Output
PB1.GPIO_Label=J105_3_SYNC_OUT
PB1.Signal=GPIO_Output
PB10.GPIO_Label=J105_1_I2C2_SCL
PB10.Mode=I2C
PB10.Signal=I2C2_SCL
PB11.GPIO_Label=J105_1_I2C2_SDA
PB11.Mode=I2C
PB11.Signal=I2C2_SDA
PB12.GPIO_Label=IIS2MDC_CSn
PB12.GPIO_PuPd=GPIO_NOPULL
PB12.PinState=GPIO_PIN_SET
PB12.Signal=GPIO_Output
PB13.GPIO_Label=MAG_SCK
PB13.Mode=Full_Duplex_Master
PB13.PinAttribute=Free
PB13.Signal=SPI2_SCK
PB14.GPIO_Label=ADIS165XX_EXT_CLK
PB14.PinAttribute=Free
PB14.Signal=S_TIM12_CH1
PB15.GPIO_Label=J105_2_SPI4_EXT_CLK 
PB15.Signal=GPIO_Output
PB2.GPIO_Label=BARO_MOSI
PB2.Mode=Full_Duplex_Master
PB2.Signal=SPI3_MOSI
PB3\ (JTDO/TRACESWO).GPIO_Label=BARO_SCK
PB3\ (JTDO/TRACESWO).Mode=Full_Duplex_Master
PB3\ (JTDO/TRACESWO).Signal=SPI3_SCK
PB4\ (NJTRST).GPIO_Label=BARO_MISO
PB4\ (NJTRST).Mode=Full_Duplex_Master
PB4\ (NJTRST).Signal=SPI3_MISO
PB5.GPIO_Label=J106_PWM10
PB5.Signal=S_TIM3_CH2
PB6.GPIO_Label=PITOT_I2C1_SCL
PB6.GPIO_Pu=GPIO_NOPULL
PB6.Mode=I2C
PB6.PinState=GPIO_PIN_SET
PB6.Signal=I2C1_SCL
PB7.GPIO_Label=GPS_UART1_RX
PB7.Mode=Asynchronous
PB7.Signal=USART1_RX
PB7.Stacked=true
PB8.GPIO_Label=ADIS165XX_DRDY
PB8.GPIO_PuPd=GPIO_PULLDOWN
PB8.Signal=GPXTI8
PB9.GPIO_Label=PITOT_I2C1_SDA
PB9.GPIO_Mode=GPIO_MODE_AF_OD
PB9.GPIO_Pu=GPIO_NOPULL
PB9.Mode=I2C
PB9.PinState=GPIO_PIN_SET
PB9.Signal=I2C1_SDA
PC0.GPIO_Label=ADC_5V0
PC0.Signal=ADCx_INP10
PC1.GPIO_Label=ADC_IBATT
PC1.Signal=ADCx_INP11
PC10.GPIO_Label=J102_SDMMC1_D2
PC10.GPIO_PuPd=GPIO_PULLUP
PC10.Mode=SD_4_bits_Wide_bus
PC10.Signal=SDMMC1_D2
PC11.GPIO_Label=J102_SDMMC1_D3
PC11.GPIO_PuPd=GPIO_PULLUP
PC11.Mode=SD_4_bits_Wide_bus
PC11.Signal=SDMMC1_D3
PC12.GPIO_Label=J102_SDMMC1_CK
PC12.GPIO_PuPd=GPIO_PULLUP
PC12.Mode=SD_4_bits_Wide_bus
PC12.Signal=SDMMC1_CK
PC13.GPIO_Label=J000_JETSON_SYNC
PC13.GPIO_PuPd=GPIO_PULLDOWN
PC13.PinAttribute=Free
PC13.Signal=GPXTI13
PC14-OSC32_IN\ (OSC32_IN).GPIO_Label=J000_JETSON_32KHZ_CLK
PC14-OSC32_IN\ (OSC32_IN).Mode=LSE-External-Clock-Source
PC14-OSC32_IN\ (OSC32_IN).PinAttribute=Free
PC14-OSC32_IN\ (OSC32_IN).Signal=RCC_OSC32_IN
PC15-OSC32_OUT\ (OSC32_OUT).GPIO_Label=TP4
PC15-OSC32_OUT\ (OSC32_OUT).PinAttribute=Free
PC15-OSC32_OUT\ (OSC32_OUT).Signal=GPIO_Output
PC2_C.GPIO_Label=MAG_MISO
PC2_C.GPIO_PuPd=GPIO_NOPULL
PC2_C.GPIO_Speed=GPIO_SPEED_FREQ_LOW
PC2_C.Mode=Full_Duplex_Master
PC2_C.Signal=SPI2_MISO
PC3_C.GPIO_Label=MAG_MOSI
PC3_C.Mode=Full_Duplex_Master
PC3_C.Signal=SPI2_MOSI
PC4.GPIO_Label=ADC_3V3
PC4.Signal=ADCx_INP4
PC5.GPIO_Label=ADC_12V
PC5.Signal=ADCx_INP8
PC6.GPIO_Label=J106_PWM09
PC6.Signal=S_TIM3_CH1
PC7.GPIO_Label=TP6
PC7.Signal=GPIO_Output
PC8.GPIO_Label=J102_SDMMC1_D0
PC8.GPIO_PuPd=GPIO_PULLUP
PC8.Mode=SD_4_bits_Wide_bus
PC8.Signal=SDMMC1_D0
PC9.GPIO_Label=J102_SDMMC1_D1
PC9.GPIO_PuPd=GPIO_PULLUP
PC9.Mode=SD_4_bits_Wide_bus
PC9.Signal=SDMMC1_D1
PD0.GPIO_Label=J105_4_CAN1_RX
PD0.Mode=FDCAN_Activate
PD0.Signal=FDCAN1_RX
PD1.GPIO_Label=J105_4_CAN1_TX
PD1.Mode=FDCAN_Activate
PD1.Signal=FDCAN1_TX
PD10.GPIO_Label=BMI088_GYRO_CSn
PD10.GPIO_PuPd=GPIO_NOPULL
PD10.PinState=GPIO_PIN_SET
PD10.Signal=GPIO_Output
PD11.GPIO_Label=DPS310_DRDY
PD11.GPIO_PuPd=GPIO_PULLDOWN
PD11.Signal=GPXTI11
PD12.GPIO_Label=J106_PWM07
PD12.Signal=S_TIM4_CH1
PD13.GPIO_Label=J106_PWM06
PD13.Signal=S_TIM4_CH2
PD14.GPIO_Label=J106_PWM05
PD14.Signal=S_TIM4_CH3
PD15.GPIO_Label=J106_PWM08
PD15.Signal=S_TIM4_CH4
PD2.GPIO_Label=J102_SDMMC1_CMD
PD2.GPIO_PuPd=GPIO_PULLUP
PD2.Mode=SD_4_bits_Wide_bus
PD2.Signal=SDMMC1_CMD
PD3.GPIO_Label=J103_1_TELEM_UART2_CTS
PD3.Signal=USART2_CTS
PD4.GPIO_Label=J103_1_TELEM_UART2_RTS
PD4.Signal=USART2_RTS
PD5.GPIO_Label=J103_1_TELEM_UART2_TX
PD5.Mode=Asynchronous
PD5.Signal=USART2_TX
PD6.GPIO_Label=J103_1_TELEM_UART2_RX
PD6.GPIO_ModeDefaultPP=GPIO_MODE_AF_OD
PD6.GPIO_PuPd=GPIO_PULLUP
PD6.Mode=Asynchronous
PD6.Signal=USART2_RX
PD7.GPIO_Label=BMI088_MOSI
PD7.Mode=Full_Duplex_Master
PD7.Signal=SPI1_MOSI
PD8.GPIO_Label=J103_2_RC_UART3_TX
PD8.Mode=Asynchronous
PD8.Signal=USART3_TX
PD9.GPIO_Label=J103_2_RC_UART3_RX
PD9.GPIO_ModeDefaultPP=GPIO_MODE_AF_OD
PD9.GPIO_PuPd=GPIO_PULLUP
PD9.Mode=Asynchronous
PD9.Signal=USART3_RX
PE0.GPIO_Label=IIS2MDC_DRDY
PE0.GPIO_PuPd=GPIO_PULLDOWN
PE0.PinAttribute=Free
PE0.Signal=GPXTI0
PE1.GPIO_Label=DPS310_CSn
PE1.GPIO_PuPd=GPIO_NOPULL
PE1.PinAttribute=Free
PE1.PinState=GPIO_PIN_SET
PE1.Signal=GPIO_Output
PE10.GPIO_Label=J105_2_DRDY
PE10.GPIO_PuPd=GPIO_PULLDOWN
PE10.Signal=GPXTI10
PE11.GPIO_Label=J106_PWM02
PE11.Signal=S_TIM1_CH2
PE12.GPIO_Label=ADIS165XX_RESET
PE12.GPIO_PuPd=GPIO_PULLDOWN
PE12.Signal=GPIO_Output
PE13.GPIO_Label=ADIS165XX_MISO
PE13.GPIO_PuPd=GPIO_PULLUP
PE13.Mode=Full_Duplex_Master
PE13.Signal=SPI4_MISO
PE14.GPIO_Label=J106_PWM04
PE14.Signal=S_TIM1_CH4
PE15.GPIO_Label=LED_GRN
PE15.Signal=GPIO_Output
PE2.GPIO_Label=ADIS165XX_SCK
PE2.Mode=Full_Duplex_Master
PE2.Signal=SPI4_SCK
PE3.GPIO_Label=J105_2_SPI4_EXT_CS
PE3.GPIO_PuPd=GPIO_NOPULL
PE3.PinAttribute=Free
PE3.PinState=GPIO_PIN_SET
PE3.Signal=GPIO_Output
PE4.GPIO_Label=ADIS165XX_CSn
PE4.Signal=GPIO_Output
PE5.GPIO_Label=J000_JETSON_DRDY
PE5.GPIO_PuPd=GPIO_NOPULL
PE5.Signal=GPIO_Output
PE6.GPIO_Label=ADIS165XX_MOSI
PE6.Mode=Full_Duplex_Master
PE6.PinAttribute=Free
PE6.Signal=SPI4_MOSI
PE7.GPIO_Label=LED_RED
PE7.Signal=GPIO_Output
PE8.GPIO_Label=LED_BLU
PE8.Signal=GPIO_Output
PE9.GPIO_Label=PITOT_DRDY
PE9.GPIO_PuPd=GPIO_PULLDOWN
PE9.Signal=GPXTI9
PH0-OSC_IN\ (PH0).GPIO_Label=EXT_OSC
PH0-OSC_IN\ (PH0).Mode=HSE-External-Clock-Source
PH0-OSC_IN\ (PH0).PinAttribute=Free
PH0-OSC_IN\ (PH0).Signal=RCC_OSC_IN
PH1-OSC_OUT\ (PH1).GPIO_Label=J105_2_SPI4_EXT_RST
PH1-OSC_OUT\ (PH1).Signal=GPIO_Input
ProjectManager.HeapSize=0x2000
ProjectManager.StackSize=0x2000
ProjectManager.TargetToolchain=STM32CubeIDE
RCC.ADCCLockSelection=RCC_ADCCLKSOURCE_PLL3
RCC.ADCFreq_Value=64000000
RCC.APB1Freq_Value=100000000
RCC.APB2Freq_Value=100000000
RCC.APB3Freq_Value=100000000
RCC.APB4Freq_Value=100000000
RCC.CortexFreq_Value=400000000
RCC.D1PPRE=RCC_APB3_DIV2
RCC.D2PPRE1=RCC_APB1_DIV2
RCC.D2PPRE2=RCC_APB2_DIV2
RCC.D3PPRE=RCC_APB4_DIV2
RCC.DIVM1=25
RCC.DIVM2=25
RCC.DIVM3=25
RCC.DIVN1=400
RCC.DIVN2=240
RCC.DIVN3=480
RCC.DIVP2=30
RCC.DIVP3=60
RCC.DIVQ1=8
RCC.DIVQ2=30
RCC.DIVQ3=20
RCC.DIVR3=15
RCC.FDCANCLockSelection=RCC_FDCANCLKSOURCE_PLL2
RCC.FLatency-AdvancedSettings=FLASH_LATENCY_0
RCC.HCLKFreq_Value=200000000
RCC.HPRE=RCC_HCLK_DIV2
RCC.HSE_VALUE=50000000
RCC.PLL1_VCI_Range-AdvancedSettings=RCC_PLL1VCIRANGE_3
RCC.PLL1_VCO_SEL-AdvancedSettings=RCC_PLL1VCOMEDIUM
RCC.PLL2_VCI_Range-AdvancedSettings=RCC_PLL2VCIRANGE_0
RCC.PLL3_VCI_Range-AdvancedSettings=RCC_PLL3VCIRANGE_1
RCC.PLLFRACN=0
RCC.ProductRev=revV
RCC.RCC_RTC_Clock_Source_FROM_HSE=RCC_RTCCLKSOURCE_HSE_DIV8
RCC.SPI123CLockSelection=RCC_SPI123CLKSOURCE_PLL2
RCC.SYSCLKFreq_VALUE=400000000
RCC.SYSCLKSource=RCC_SYSCLKSOURCE_PLLCLK
RCC.Spi45ClockSelection=RCC_SPI45CLKSOURCE_PLL2
RCC.USBCLockSelection=RCC_USBCLKSOURCE_PLL3
RCC.USBFreq_Value=48000000
SDMMC1.ClockDiv=10
SH.ADCx_INP10.0=ADC1_INP10,IN10-Single-Ended
SH.ADCx_INP11.0=ADC1_INP11,IN11-Single-Ended
SH.ADCx_INP4.0=ADC1_INP4,IN4-Single-Ended
SH.ADCx_INP7.0=ADC1_INP7,IN7-Single-Ended
SH.ADCx_INP8.0=ADC1_INP8,IN8-Single-Ended
SH.S_TIM12_CH1.0=TIM12_CH1,PWM Generation1 CH1
SH.S_TIM1_CH1.0=TIM1_CH1,PWM Generation1 CH1
SH.S_TIM1_CH2.0=TIM1_CH2,PWM Generation2 CH2
SH.S_TIM1_CH3.0=TIM1_CH3,PWM Generation3 CH3
SH.S_TIM1_CH4.0=TIM1_CH4,PWM Generation4 CH4
SH.S_TIM3_CH1.0=TIM3_CH1,PWM Generation1 CH1
SH.S_TIM3_CH2.0=TIM3_CH2,PWM Generation2 CH2
SH.S_TIM4_CH1.0=TIM4_CH1,PWM Generation1 CH1
SH.S_TIM4_CH2.0=TIM4_CH2,PWM Generation2 CH2
SH.S_TIM4_CH3.0=TIM4_CH3,PWM Generation3 CH3
SH.S_TIM4_CH4.0=TIM4_CH4,PWM Generation4 CH4
SPI1.BaudRatePrescaler=SPI_BAUDRATEPRESCALER_4
SPI1.CLKPhase=SPI_PHASE_2EDGE
SPI1.CLKPolarity=SPI_POLARITY_HIGH
SPI1.CalculateBaudRate=4.0 MBits/s
SPI1.DataSize=SPI_DATASIZE_8BIT
SPI1.Direction=SPI_DIRECTION_2LINES
SPI1.MasterKeepIOState=SPI_MASTER_KEEP_IO_STATE_ENABLE
SPI1.Mode=SPI_MODE_MASTER
SPI1.VirtualType=VM_MASTER
SPI2.BaudRatePrescaler=SPI_BAUDRATEPRESCALER_4
SPI2.CLKPhase=SPI_PHASE_2EDGE
SPI2.CLKPolarity=SPI_POLARITY_HIGH
SPI2.CalculateBaudRate=4.0 MBits/s
SPI2.DataSize=SPI_DATASIZE_8BIT
SPI2.Direction=SPI_DIRECTION_2LINES
SPI2.MasterKeepIOState=SPI_MASTER_KEEP_IO_STATE_ENABLE
SPI2.Mode=SPI_MODE_MASTER
SPI2.VirtualType=VM_MASTER
SPI3.BaudRatePrescaler=SPI_BAUDRATEPRESCALER_4
SPI3.CLKPhase=SPI_PHASE_2EDGE
SPI3.CLKPolarity=SPI_POLARITY_HIGH
SPI3.CalculateBaudRate=4.0 MBits/s
SPI3.DataSize=SPI_DATASIZE_8BIT
SPI3.Direction=SPI_DIRECTION_2LINES
SPI3.MasterKeepIOState=SPI_MASTER_KEEP_IO_STATE_ENABLE
SPI3.Mode=SPI_MODE_MASTER
SPI3.VirtualType=VM_MASTER
SPI4.BaudRatePrescaler=SPI_BAUDRATEPRESCALER_16
SPI4.CLKPhase=SPI_PHASE_2EDGE
SPI4.CLKPolarity=SPI_POLARITY_HIGH
SPI4.CalculateBaudRate=1000.0 KBits/s
SPI4.DataSize=SPI_DATASIZE_8BIT
SPI4.Direction=SPI_DIRECTION_2LINES
SPI4.MasterInterDataIdleness=SPI_MASTER_INTERDATA_IDLENESS_01CYCLE
SPI4.MasterKeepIOState=SPI_MASTER_KEEP_IO_STATE_ENABLE
SPI4.MasterSSIdleness=SPI_MASTER_SS_IDLENESS_00CYCLE
SPI4.Mode=SPI_MODE_MASTER
SPI4.VirtualType=VM_MASTER
TIM1.AutoReloadPreload=TIM_AUTORELOAD_PRELOAD_ENABLE
TIM1.Channel-PWM\ Generation1\ CH1=TIM_CHANNEL_1
TIM1.Channel-PWM\ Generation2\ CH2=TIM_CHANNEL_2
TIM1.Channel-PWM\ Generation3\ CH3=TIM_CHANNEL_3
TIM1.Channel-PWM\ Generation4\ CH4=TIM_CHANNEL_4
TIM1.Period=(20000)
TIM1.Prescaler=(199)
TIM1.Pulse-PWM\ Generation1\ CH1=(1500)
TIM1.Pulse-PWM\ Generation2\ CH2=(1500)
TIM1.Pulse-PWM\ Generation3\ CH3=(1500)
TIM1.Pulse-PWM\ Generation4\ CH4=(1500)
TIM12.AutoReloadPreload=TIM_AUTORELOAD_PRELOAD_ENABLE
TIM12.Channel-PWM\ Generation1\ CH1=TIM_CHANNEL_1
TIM12.Channel-PWM\ Generation2\ CH2=TIM_CHANNEL_2
TIM12.Period=(ADIS165XX_TIM_PERIOD_US)
TIM12.Prescaler=199
TIM12.Pulse-PWM\ Generation1\ CH1=250
TIM17.Period=299
TIM17.Prescaler=199
TIM3.AutoReloadPreload=TIM_AUTORELOAD_PRELOAD_ENABLE
TIM3.Channel-PWM\ Generation1\ CH1=TIM_CHANNEL_1
TIM3.Channel-PWM\ Generation2\ CH2=TIM_CHANNEL_2
TIM3.Period=(20000)
TIM3.Prescaler=(199)
TIM3.Pulse-PWM\ Generation1\ CH1=(1500)
TIM3.Pulse-PWM\ Generation2\ CH2=(1500)
TIM4.AutoReloadPreload=TIM_AUTORELOAD_PRELOAD_ENABLE
TIM4.Channel-Input_Capture1_from_TI1=TIM_CHANNEL_1
TIM4.Channel-PWM\ Generation1\ CH1=TIM_CHANNEL_1
TIM4.Channel-PWM\ Generation2\ CH2=TIM_CHANNEL_2
TIM4.Channel-PWM\ Generation3\ CH3=TIM_CHANNEL_3
TIM4.Channel-PWM\ Generation4\ CH4=TIM_CHANNEL_4
TIM4.Period=(20000)
TIM4.Prescaler=(199)
TIM4.Pulse-PWM\ Generation1\ CH1=(1500)
TIM4.Pulse-PWM\ Generation2\ CH2=(1500)
TIM4.Pulse-PWM\ Generation3\ CH3=(1500)
TIM4.Pulse-PWM\ Generation4\ CH4=(1500)
TIM5.Period=0xffffffff
TIM5.Prescaler=199
TIM5.TIM_MasterOutputTrigger=TIM_TRGO_UPDATE
TIM7.AutoReloadPreload=TIM_AUTORELOAD_PRELOAD_ENABLE
TIM7.Period=(POLLING_PERIOD_US)
TIM7.Prescaler=199
USART1.VirtualMode-Asynchronous=VM_ASYNC
USART2.BaudRate=(UART2_BAUD)
USART2.FIFOMode=FIFOMODE_DISABLE
USART2.RXFIFOThreshold=RXFIFO_THRESHOLD_1EIGHTHFULL
USART2.StopBits=STOPBITS_1
USART2.TXFIFOThreshold=TXFIFO_THRESHOLD_1EIGHTHFULL
USART2.VirtualMode-Asynchronous=VM_ASYNC
USART3.BaudRate=100000
USART3.DataInvertParam=ADVFEATURE_DATAINV_DISABLE
USART3.Parity=PARITY_EVEN
USART3.RxPinLevelInvertParam=ADVFEATURE_RXINV_ENABLE
USART3.StopBits=STOPBITS_2
USART3.TxPinLevelInvertParam=ADVFEATURE_TXINV_ENABLE
USART3.VirtualMode-Asynchronous=VM_ASYNC
USART3.WordLength=WORDLENGTH_9B
USB_OTG_FS.VirtualMode=Device_Only
VP_ADC3_TempSens_Input.Mode=IN-TempSens
VP_ADC3_Vbat_Input.Mode=IN-Vbat
VP_ADC3_Vref_Input.Mode=IN-Vrefint
VP_CRC_VS_CRC.Mode=CRC_Activate
VP_RNG_VS_RNG.Mode=RNG_Activate
VP_RTC_VS_RTC_Activate.Mode=RTC_Enabled
VP_TIM17_VS_ClockSourceINT.Mode=Enable_Timer
VP_TIM5_VS_ClockSourceINT.Mode=Internal
VP_TIM7_VS_ClockSourceINT.Mode=Enable_Timer
VP_TIM8_VS_ClockSourceITR.Mode=TriggerSource_ITR3
VP_TIM8_VS_ControllerModeClock.Mode=Clock Mode
board=custom

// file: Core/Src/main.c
/* USER CODE BEGIN Header */
/**
  ******************************************************************************
  * @file           : main.c
  * @brief          : Main program body
  ******************************************************************************
  * @attention
  *
  * Copyright (c) 2023 STMicroelectronics.
  * All rights reserved.
  *
  * This software is licensed under terms that can be found in the LICENSE file
  * in the root directory of this software component.
  * If no LICENSE file comes with this software, it is provided AS-IS.
  *
  ******************************************************************************
  */
/* USER CODE END Header */
#include "main.h"

ADC_HandleTypeDef hadc1;
ADC_HandleTypeDef hadc3;
DMA_HandleTypeDef hdma_adc1;
DMA_HandleTypeDef hdma_adc3;

CRC_HandleTypeDef hcrc;

FDCAN_HandleTypeDef hfdcan1;

I2C_HandleTypeDef hi2c1;
I2C_HandleTypeDef hi2c2;
DMA_HandleTypeDef hdma_i2c1_rx;
DMA_HandleTypeDef hdma_i2c1_tx;
DMA_HandleTypeDef hdma_i2c2_rx;
DMA_HandleTypeDef hdma_i2c2_tx;

RNG_HandleTypeDef hrng;

RTC_HandleTypeDef hrtc;

SD_HandleTypeDef hsd1;

SPI_HandleTypeDef hspi1;
SPI_HandleTypeDef hspi2;
SPI_HandleTypeDef hspi3;
SPI_HandleTypeDef hspi4;
DMA_HandleTypeDef hdma_spi1_rx;
DMA_HandleTypeDef hdma_spi1_tx;
DMA_HandleTypeDef hdma_spi2_rx;
DMA_HandleTypeDef hdma_spi2_tx;
DMA_HandleTypeDef hdma_spi3_rx;
DMA_HandleTypeDef hdma_spi3_tx;
DMA_HandleTypeDef hdma_spi4_rx;
DMA_HandleTypeDef hdma_spi4_tx;

TIM_HandleTypeDef htim1;
TIM_HandleTypeDef htim3;
TIM_HandleTypeDef htim4;
TIM_HandleTypeDef htim5;
TIM_HandleTypeDef htim7;
TIM_HandleTypeDef htim8;
TIM_HandleTypeDef htim12;
TIM_HandleTypeDef htim17;

UART_HandleTypeDef huart1;
UART_HandleTypeDef huart2;
UART_HandleTypeDef huart3;
DMA_HandleTypeDef hdma_usart1_rx;
DMA_HandleTypeDef hdma_usart2_tx;
DMA_HandleTypeDef hdma_usart3_rx;

PCD_HandleTypeDef hpcd_USB_OTG_FS;

/* USER CODE BEGIN PV */
#include "CommonConfig.h"
#if 0
/* USER CODE END PV */

void SystemClock_Config(void);
void PeriphCommonClock_Config(void);
static void MPU_Config(void);

int main(void)
{

  /* MPU Configuration--------------------------------------------------------*/
  MPU_Config();
/* Enable the CPU Cache */

  /* Enable I-Cache---------------------------------------------------------*/
  SCB_EnableICache();

  /* Enable D-Cache---------------------------------------------------------*/
  SCB_EnableDCache();

  /* MCU Configuration--------------------------------------------------------*/

  /* Reset of all peripherals, Initializes the Flash interface and the Systick. */
  HAL_Init();

  /* Configure the system clock */
  SystemClock_Config();

/* Configure the peripherals common clocks */
  PeriphCommonClock_Config();

  /* Initialize all configured peripherals */
  MX_GPIO_Init();
  MX_DMA_Init();
  MX_BDMA_Init();
  MX_SPI1_Init();
  MX_SPI2_Init();
  MX_SPI3_Init();
  MX_SPI4_Init();
  MX_TIM1_Init();
  MX_TIM3_Init();
  MX_TIM4_Init();
  MX_TIM5_Init();
  MX_TIM8_Init();
  MX_TIM7_Init();
  MX_TIM12_Init();
  MX_USART2_UART_Init();
  MX_USART3_UART_Init();
  MX_ADC1_Init();
  MX_ADC3_Init();
  MX_FDCAN1_Init();
  MX_SDMMC1_SD_Init();
  MX_RTC_Init();
  MX_CRC_Init();
  MX_RNG_Init();
  MX_I2C2_Init();
  MX_USB_OTG_FS_PCD_Init();
  MX_I2C1_Init();
  MX_USART1_UART_Init();
  MX_TIM17_Init();

  /* Infinite loop */
  while (1)
  {

    /* USER CODE BEGIN 3 */
  }
#endif
  void dummy(void) {
  /* USER CODE END 3 */
}

void SystemClock_Config(void)
{
  RCC_OscInitTypeDef RCC_OscInitStruct = {0};
  RCC_ClkInitTypeDef RCC_ClkInitStruct = {0};

  /** Supply configuration update enable
  */
  HAL_PWREx_ConfigSupply(PWR_LDO_SUPPLY);

  /** Configure the main internal regulator output voltage
  */
  __HAL_PWR_VOLTAGESCALING_CONFIG(PWR_REGULATOR_VOLTAGE_SCALE1);

  while(!__HAL_PWR_GET_FLAG(PWR_FLAG_VOSRDY)) {}

  /** Initializes the RCC Oscillators according to the specified parameters
  * in the RCC_OscInitTypeDef structure.
  */
  RCC_OscInitStruct.OscillatorType = RCC_OSCILLATORTYPE_HSI48|RCC_OSCILLATORTYPE_LSI
                              |RCC_OSCILLATORTYPE_HSE;
  RCC_OscInitStruct.HSEState = RCC_HSE_BYPASS;
  RCC_OscInitStruct.LSIState = RCC_LSI_ON;
  RCC_OscInitStruct.HSI48State = RCC_HSI48_ON;
  RCC_OscInitStruct.PLL.PLLState = RCC_PLL_ON;
  RCC_OscInitStruct.PLL.PLLSource = RCC_PLLSOURCE_HSE;
  RCC_OscInitStruct.PLL.PLLM = 25;
  RCC_OscInitStruct.PLL.PLLN = 400;
  RCC_OscInitStruct.PLL.PLLP = 2;
  RCC_OscInitStruct.PLL.PLLQ = 8;
  RCC_OscInitStruct.PLL.PLLR = 2;
  RCC_OscInitStruct.PLL.PLLRGE = RCC_PLL1VCIRANGE_1;
  RCC_OscInitStruct.PLL.PLLVCOSEL = RCC_PLL1VCOWIDE;
  RCC_OscInitStruct.PLL.PLLFRACN = 0;
  if (HAL_RCC_OscConfig(&RCC_OscInitStruct) != HAL_OK)
  {
    Error_Handler();
  }

  /** Initializes the CPU, AHB and APB buses clocks
  */
  RCC_ClkInitStruct.ClockType = RCC_CLOCKTYPE_HCLK|RCC_CLOCKTYPE_SYSCLK
                              |RCC_CLOCKTYPE_PCLK1|RCC_CLOCKTYPE_PCLK2
                              |RCC_CLOCKTYPE_D3PCLK1|RCC_CLOCKTYPE_D1PCLK1;
  RCC_ClkInitStruct.SYSCLKSource = RCC_SYSCLKSOURCE_PLLCLK;
  RCC_ClkInitStruct.SYSCLKDivider = RCC_SYSCLK_DIV1;
  RCC_ClkInitStruct.AHBCLKDivider = RCC_HCLK_DIV2;
  RCC_ClkInitStruct.APB3CLKDivider = RCC_APB3_DIV2;
  RCC_ClkInitStruct.APB1CLKDivider = RCC_APB1_DIV2;
  RCC_ClkInitStruct.APB2CLKDivider = RCC_APB2_DIV2;
  RCC_ClkInitStruct.APB4CLKDivider = RCC_APB4_DIV2;

  if (HAL_RCC_ClockConfig(&RCC_ClkInitStruct, FLASH_LATENCY_2) != HAL_OK)
  {
    Error_Handler();
  }
}

void PeriphCommonClock_Config(void)
{
  RCC_PeriphCLKInitTypeDef PeriphClkInitStruct = {0};

  /** Initializes the peripherals clock
  */
  PeriphClkInitStruct.PeriphClockSelection = RCC_PERIPHCLK_USB|RCC_PERIPHCLK_ADC
                              |RCC_PERIPHCLK_SPI3|RCC_PERIPHCLK_SPI2
                              |RCC_PERIPHCLK_SPI1|RCC_PERIPHCLK_SPI4
                              |RCC_PERIPHCLK_FDCAN;
  PeriphClkInitStruct.PLL2.PLL2M = 25;
  PeriphClkInitStruct.PLL2.PLL2N = 240;
  PeriphClkInitStruct.PLL2.PLL2P = 30;
  PeriphClkInitStruct.PLL2.PLL2Q = 30;
  PeriphClkInitStruct.PLL2.PLL2R = 2;
  PeriphClkInitStruct.PLL2.PLL2RGE = RCC_PLL2VCIRANGE_1;
  PeriphClkInitStruct.PLL2.PLL2VCOSEL = RCC_PLL2VCOWIDE;
  PeriphClkInitStruct.PLL2.PLL2FRACN = 0;
  PeriphClkInitStruct.PLL3.PLL3M = 25;
  PeriphClkInitStruct.PLL3.PLL3N = 480;
  PeriphClkInitStruct.PLL3.PLL3P = 60;
  PeriphClkInitStruct.PLL3.PLL3Q = 20;
  PeriphClkInitStruct.PLL3.PLL3R = 15;
  PeriphClkInitStruct.PLL3.PLL3RGE = RCC_PLL3VCIRANGE_1;
  PeriphClkInitStruct.PLL3.PLL3VCOSEL = RCC_PLL3VCOWIDE;
  PeriphClkInitStruct.PLL3.PLL3FRACN = 0;
  PeriphClkInitStruct.Spi123ClockSelection = RCC_SPI123CLKSOURCE_PLL2;
  PeriphClkInitStruct.Spi45ClockSelection = RCC_SPI45CLKSOURCE_PLL2;
  PeriphClkInitStruct.FdcanClockSelection = RCC_FDCANCLKSOURCE_PLL2;
  PeriphClkInitStruct.UsbClockSelection = RCC_USBCLKSOURCE_PLL3;
  PeriphClkInitStruct.AdcClockSelection = RCC_ADCCLKSOURCE_PLL3;
  if (HAL_RCCEx_PeriphCLKConfig(&PeriphClkInitStruct) != HAL_OK)
  {
    Error_Handler();
  }
}

void MX_ADC1_Init(void)
{

  ADC_MultiModeTypeDef multimode = {0};
  ADC_ChannelConfTypeDef sConfig = {0};

  /** Common config
  */
  hadc1.Instance = ADC1;
  hadc1.Init.ClockPrescaler = ADC_CLOCK_ASYNC_DIV32;
  hadc1.Init.Resolution = ADC_RESOLUTION_16B;
  hadc1.Init.ScanConvMode = ADC_SCAN_ENABLE;
  hadc1.Init.EOCSelection = ADC_EOC_SEQ_CONV;
  hadc1.Init.LowPowerAutoWait = DISABLE;
  hadc1.Init.ContinuousConvMode = DISABLE;
  hadc1.Init.NbrOfConversion = 6;
  hadc1.Init.DiscontinuousConvMode = DISABLE;
  hadc1.Init.ExternalTrigConv = ADC_SOFTWARE_START;
  hadc1.Init.ExternalTrigConvEdge = ADC_EXTERNALTRIGCONVEDGE_NONE;
  hadc1.Init.ConversionDataManagement = ADC_CONVERSIONDATA_DMA_ONESHOT;
  hadc1.Init.Overrun = ADC_OVR_DATA_PRESERVED;
  hadc1.Init.LeftBitShift = ADC_LEFTBITSHIFT_NONE;
  hadc1.Init.OversamplingMode = DISABLE;
  if (HAL_ADC_Init(&hadc1) != HAL_OK)
  {
    Error_Handler();
  }

  /** Configure the ADC multi-mode
  */
  multimode.Mode = ADC_MODE_INDEPENDENT;
  if (HAL_ADCEx_MultiModeConfigChannel(&hadc1, &multimode) != HAL_OK)
  {
    Error_Handler();
  }

  /** Configure Regular Channel
  */
  sConfig.Channel = ADC_CHANNEL_4;
  sConfig.Rank = ADC_REGULAR_RANK_1;
  sConfig.SamplingTime = ADC_SAMPLETIME_810CYCLES_5;
  sConfig.SingleDiff = ADC_SINGLE_ENDED;
  sConfig.OffsetNumber = ADC_OFFSET_NONE;
  sConfig.Offset = 0;
  sConfig.OffsetSignedSaturation = DISABLE;
  if (HAL_ADC_ConfigChannel(&hadc1, &sConfig) != HAL_OK)
  {
    Error_Handler();
  }

  /** Configure Regular Channel
  */
  sConfig.Channel = ADC_CHANNEL_7;
  sConfig.Rank = ADC_REGULAR_RANK_2;
  if (HAL_ADC_ConfigChannel(&hadc1, &sConfig) != HAL_OK)
  {
    Error_Handler();
  }

  /** Configure Regular Channel
  */
  sConfig.Channel = ADC_CHANNEL_8;
  sConfig.Rank = ADC_REGULAR_RANK_3;
  if (HAL_ADC_ConfigChannel(&hadc1, &sConfig) != HAL_OK)
  {
    Error_Handler();
  }

  /** Configure Regular Channel
  */
  sConfig.Channel = ADC_CHANNEL_10;
  sConfig.Rank = ADC_REGULAR_RANK_4;
  if (HAL_ADC_ConfigChannel(&hadc1, &sConfig) != HAL_OK)
  {
    Error_Handler();
  }

  /** Configure Regular Channel
  */
  sConfig.Channel = ADC_CHANNEL_11;
  sConfig.Rank = ADC_REGULAR_RANK_5;
  if (HAL_ADC_ConfigChannel(&hadc1, &sConfig) != HAL_OK)
  {
    Error_Handler();
  }

  /** Configure Regular Channel
  */
  sConfig.Channel = ADC_CHANNEL_16;
  sConfig.Rank = ADC_REGULAR_RANK_6;
  if (HAL_ADC_ConfigChannel(&hadc1, &sConfig) != HAL_OK)
  {
    Error_Handler();
  }

}

void MX_ADC3_Init(void)
{

  ADC_ChannelConfTypeDef sConfig = {0};

  /** Common config
  */
  hadc3.Instance = ADC3;
  hadc3.Init.ClockPrescaler = ADC_CLOCK_ASYNC_DIV32;
  hadc3.Init.Resolution = ADC_RESOLUTION_16B;
  hadc3.Init.ScanConvMode = ADC_SCAN_ENABLE;
  hadc3.Init.EOCSelection = ADC_EOC_SEQ_CONV;
  hadc3.Init.LowPowerAutoWait = DISABLE;
  hadc3.Init.ContinuousConvMode = DISABLE;
  hadc3.Init.NbrOfConversion = 3;
  hadc3.Init.DiscontinuousConvMode = DISABLE;
  hadc3.Init.ExternalTrigConv = ADC_SOFTWARE_START;
  hadc3.Init.ExternalTrigConvEdge = ADC_EXTERNALTRIGCONVEDGE_NONE;
  hadc3.Init.ConversionDataManagement = ADC_CONVERSIONDATA_DMA_ONESHOT;
  hadc3.Init.Overrun = ADC_OVR_DATA_PRESERVED;
  hadc3.Init.LeftBitShift = ADC_LEFTBITSHIFT_NONE;
  hadc3.Init.OversamplingMode = DISABLE;
  if (HAL_ADC_Init(&hadc3) != HAL_OK)
  {
    Error_Handler();
  }

  /** Configure Regular Channel
  */
  sConfig.Channel = ADC_CHANNEL_TEMPSENSOR;
  sConfig.Rank = ADC_REGULAR_RANK_1;
  sConfig.SamplingTime = ADC_SAMPLETIME_810CYCLES_5;
  sConfig.SingleDiff = ADC_SINGLE_ENDED;
  sConfig.OffsetNumber = ADC_OFFSET_NONE;
  sConfig.Offset = 0;
  sConfig.OffsetSignedSaturation = DISABLE;
  if (HAL_ADC_ConfigChannel(&hadc3, &sConfig) != HAL_OK)
  {
    Error_Handler();
  }

  /** Configure Regular Channel
  */
  sConfig.Channel = ADC_CHANNEL_VBAT;
  sConfig.Rank = ADC_REGULAR_RANK_2;
  if (HAL_ADC_ConfigChannel(&hadc3, &sConfig) != HAL_OK)
  {
    Error_Handler();
  }

  /** Configure Regular Channel
  */
  sConfig.Channel = ADC_CHANNEL_VREFINT;
  sConfig.Rank = ADC_REGULAR_RANK_3;
  if (HAL_ADC_ConfigChannel(&hadc3, &sConfig) != HAL_OK)
  {
    Error_Handler();
  }

}

void MX_CRC_Init(void)
{

  hcrc.Instance = CRC;
  hcrc.Init.DefaultPolynomialUse = DEFAULT_POLYNOMIAL_ENABLE;
  hcrc.Init.DefaultInitValueUse = DEFAULT_INIT_VALUE_ENABLE;
  hcrc.Init.InputDataInversionMode = CRC_INPUTDATA_INVERSION_NONE;
  hcrc.Init.OutputDataInversionMode = CRC_OUTPUTDATA_INVERSION_DISABLE;
  hcrc.InputDataFormat = CRC_INPUTDATA_FORMAT_BYTES;
  if (HAL_CRC_Init(&hcrc) != HAL_OK)
  {
    Error_Handler();
  }

}

void MX_FDCAN1_Init(void)
{

  hfdcan1.Instance = FDCAN1;
  hfdcan1.Init.FrameFormat = FDCAN_FRAME_CLASSIC;
  hfdcan1.Init.Mode = FDCAN_MODE_NORMAL;
  hfdcan1.Init.AutoRetransmission = DISABLE;
  hfdcan1.Init.TransmitPause = DISABLE;
  hfdcan1.Init.ProtocolException = DISABLE;
  hfdcan1.Init.NominalPrescaler = 16;
  hfdcan1.Init.NominalSyncJumpWidth = 1;
  hfdcan1.Init.NominalTimeSeg1 = 2;
  hfdcan1.Init.NominalTimeSeg2 = 2;
  hfdcan1.Init.DataPrescaler = 1;
  hfdcan1.Init.DataSyncJumpWidth = 1;
  hfdcan1.Init.DataTimeSeg1 = 1;
  hfdcan1.Init.DataTimeSeg2 = 1;
  hfdcan1.Init.MessageRAMOffset = 0;
  hfdcan1.Init.StdFiltersNbr = 0;
  hfdcan1.Init.ExtFiltersNbr = 0;
  hfdcan1.Init.RxFifo0ElmtsNbr = 0;
  hfdcan1.Init.RxFifo0ElmtSize = FDCAN_DATA_BYTES_8;
  hfdcan1.Init.RxFifo1ElmtsNbr = 0;
  hfdcan1.Init.RxFifo1ElmtSize = FDCAN_DATA_BYTES_8;
  hfdcan1.Init.RxBuffersNbr = 0;
  hfdcan1.Init.RxBufferSize = FDCAN_DATA_BYTES_8;
  hfdcan1.Init.TxEventsNbr = 0;
  hfdcan1.Init.TxBuffersNbr = 0;
  hfdcan1.Init.TxFifoQueueElmtsNbr = 0;
  hfdcan1.Init.TxFifoQueueMode = FDCAN_TX_FIFO_OPERATION;
  hfdcan1.Init.TxElmtSize = FDCAN_DATA_BYTES_8;
  if (HAL_FDCAN_Init(&hfdcan1) != HAL_OK)
  {
    Error_Handler();
  }

}

void MX_I2C1_Init(void)
{

  hi2c1.Instance = I2C1;
  hi2c1.Init.Timing = 0x10C0ECFF;
  hi2c1.Init.OwnAddress1 = 0;
  hi2c1.Init.AddressingMode = I2C_ADDRESSINGMODE_7BIT;
  hi2c1.Init.DualAddressMode = I2C_DUALADDRESS_DISABLE;
  hi2c1.Init.OwnAddress2 = 0;
  hi2c1.Init.OwnAddress2Masks = I2C_OA2_NOMASK;
  hi2c1.Init.GeneralCallMode = I2C_GENERALCALL_DISABLE;
  hi2c1.Init.NoStretchMode = I2C_NOSTRETCH_DISABLE;
  if (HAL_I2C_Init(&hi2c1) != HAL_OK)
  {
    Error_Handler();
  }

  /** Configure Analogue filter
  */
  if (HAL_I2CEx_ConfigAnalogFilter(&hi2c1, I2C_ANALOGFILTER_ENABLE) != HAL_OK)
  {
    Error_Handler();
  }

  /** Configure Digital filter
  */
  if (HAL_I2CEx_ConfigDigitalFilter(&hi2c1, 0) != HAL_OK)
  {
    Error_Handler();
  }

}

void MX_I2C2_Init(void)
{

  hi2c2.Instance = I2C2;
  hi2c2.Init.Timing = 0x10C0ECFF;
  hi2c2.Init.OwnAddress1 = 0;
  hi2c2.Init.AddressingMode = I2C_ADDRESSINGMODE_7BIT;
  hi2c2.Init.DualAddressMode = I2C_DUALADDRESS_DISABLE;
  hi2c2.Init.OwnAddress2 = 0;
  hi2c2.Init.OwnAddress2Masks = I2C_OA2_NOMASK;
  hi2c2.Init.GeneralCallMode = I2C_GENERALCALL_DISABLE;
  hi2c2.Init.NoStretchMode = I2C_NOSTRETCH_DISABLE;
  if (HAL_I2C_Init(&hi2c2) != HAL_OK)
  {
    Error_Handler();
  }

  /** Configure Analogue filter
  */
  if (HAL_I2CEx_ConfigAnalogFilter(&hi2c2, I2C_ANALOGFILTER_ENABLE) != HAL_OK)
  {
    Error_Handler();
  }

  /** Configure Digital filter
  */
  if (HAL_I2CEx_ConfigDigitalFilter(&hi2c2, 0) != HAL_OK)
  {
    Error_Handler();
  }

}

void MX_RNG_Init(void)
{

  hrng.Instance = RNG;
  hrng.Init.ClockErrorDetection = RNG_CED_ENABLE;
  if (HAL_RNG_Init(&hrng) != HAL_OK)
  {
    Error_Handler();
  }

}

void MX_RTC_Init(void)
{

  /** Initialize RTC Only
  */
  hrtc.Instance = RTC;
  hrtc.Init.HourFormat = RTC_HOURFORMAT_24;
  hrtc.Init.AsynchPrediv = 127;
  hrtc.Init.SynchPrediv = 255;
  hrtc.Init.OutPut = RTC_OUTPUT_DISABLE;
  hrtc.Init.OutPutPolarity = RTC_OUTPUT_POLARITY_HIGH;
  hrtc.Init.OutPutType = RTC_OUTPUT_TYPE_OPENDRAIN;
  hrtc.Init.OutPutRemap = RTC_OUTPUT_REMAP_NONE;
  if (HAL_RTC_Init(&hrtc) != HAL_OK)
  {
    Error_Handler();
  }

}

void MX_SDMMC1_SD_Init(void)
{

  /* USER CODE BEGIN SDMMC1_Init 0 */
  hsd1.Instance = SDMMC1;
  hsd1.Init.ClockEdge = SDMMC_CLOCK_EDGE_RISING;
  hsd1.Init.ClockPowerSave = SDMMC_CLOCK_POWER_SAVE_DISABLE;
  hsd1.Init.BusWide = SDMMC_BUS_WIDE_4B;
  hsd1.Init.HardwareFlowControl = SDMMC_HARDWARE_FLOW_CONTROL_DISABLE;
  hsd1.Init.ClockDiv = 10;
  if (HAL_SD_Init(&hsd1) != HAL_OK)
  {
   // Error_Handler();
  }
  return;
  /* USER CODE END SDMMC1_Init 0 */

  hsd1.Instance = SDMMC1;
  hsd1.Init.ClockEdge = SDMMC_CLOCK_EDGE_RISING;
  hsd1.Init.ClockPowerSave = SDMMC_CLOCK_POWER_SAVE_DISABLE;
  hsd1.Init.BusWide = SDMMC_BUS_WIDE_4B;
  hsd1.Init.HardwareFlowControl = SDMMC_HARDWARE_FLOW_CONTROL_DISABLE;
  hsd1.Init.ClockDiv = 10;
  if (HAL_SD_Init(&hsd1) != HAL_OK)
  {
    Error_Handler();
  }

}

void MX_SPI1_Init(void)
{

  /* SPI1 parameter configuration*/
  hspi1.Instance = SPI1;
  hspi1.Init.Mode = SPI_MODE_MASTER;
  hspi1.Init.Direction = SPI_DIRECTION_2LINES;
  hspi1.Init.DataSize = SPI_DATASIZE_8BIT;
  hspi1.Init.CLKPolarity = SPI_POLARITY_HIGH;
  hspi1.Init.CLKPhase = SPI_PHASE_2EDGE;
  hspi1.Init.NSS = SPI_NSS_SOFT;
  hspi1.Init.BaudRatePrescaler = SPI_BAUDRATEPRESCALER_4;
  hspi1.Init.FirstBit = SPI_FIRSTBIT_MSB;
  hspi1.Init.TIMode = SPI_TIMODE_DISABLE;
  hspi1.Init.CRCCalculation = SPI_CRCCALCULATION_DISABLE;
  hspi1.Init.CRCPolynomial = 0x0;
  hspi1.Init.NSSPMode = SPI_NSS_PULSE_ENABLE;
  hspi1.Init.NSSPolarity = SPI_NSS_POLARITY_LOW;
  hspi1.Init.FifoThreshold = SPI_FIFO_THRESHOLD_01DATA;
  hspi1.Init.TxCRCInitializationPattern = SPI_CRC_INITIALIZATION_ALL_ZERO_PATTERN;
  hspi1.Init.RxCRCInitializationPattern = SPI_CRC_INITIALIZATION_ALL_ZERO_PATTERN;
  hspi1.Init.MasterSSIdleness = SPI_MASTER_SS_IDLENESS_00CYCLE;
  hspi1.Init.MasterInterDataIdleness = SPI_MASTER_INTERDATA_IDLENESS_00CYCLE;
  hspi1.Init.MasterReceiverAutoSusp = SPI_MASTER_RX_AUTOSUSP_DISABLE;
  hspi1.Init.MasterKeepIOState = SPI_MASTER_KEEP_IO_STATE_ENABLE;
  hspi1.Init.IOSwap = SPI_IO_SWAP_DISABLE;
  if (HAL_SPI_Init(&hspi1) != HAL_OK)
  {
    Error_Handler();
  }

}

void MX_SPI2_Init(void)
{

  /* SPI2 parameter configuration*/
  hspi2.Instance = SPI2;
  hspi2.Init.Mode = SPI_MODE_MASTER;
  hspi2.Init.Direction = SPI_DIRECTION_2LINES;
  hspi2.Init.DataSize = SPI_DATASIZE_8BIT;
  hspi2.Init.CLKPolarity = SPI_POLARITY_HIGH;
  hspi2.Init.CLKPhase = SPI_PHASE_2EDGE;
  hspi2.Init.NSS = SPI_NSS_SOFT;
  hspi2.Init.BaudRatePrescaler = SPI_BAUDRATEPRESCALER_4;
  hspi2.Init.FirstBit = SPI_FIRSTBIT_MSB;
  hspi2.Init.TIMode = SPI_TIMODE_DISABLE;
  hspi2.Init.CRCCalculation = SPI_CRCCALCULATION_DISABLE;
  hspi2.Init.CRCPolynomial = 0x0;
  hspi2.Init.NSSPMode = SPI_NSS_PULSE_ENABLE;
  hspi2.Init.NSSPolarity = SPI_NSS_POLARITY_LOW;
  hspi2.Init.FifoThreshold = SPI_FIFO_THRESHOLD_01DATA;
  hspi2.Init.TxCRCInitializationPattern = SPI_CRC_INITIALIZATION_ALL_ZERO_PATTERN;
  hspi2.Init.RxCRCInitializationPattern = SPI_CRC_INITIALIZATION_ALL_ZERO_PATTERN;
  hspi2.Init.MasterSSIdleness = SPI_MASTER_SS_IDLENESS_00CYCLE;
  hspi2.Init.MasterInterDataIdleness = SPI_MASTER_INTERDATA_IDLENESS_00CYCLE;
  hspi2.Init.MasterReceiverAutoSusp = SPI_MASTER_RX_AUTOSUSP_DISABLE;
  hspi2.Init.MasterKeepIOState = SPI_MASTER_KEEP_IO_STATE_ENABLE;
  hspi2.Init.IOSwap = SPI_IO_SWAP_DISABLE;
  if (HAL_SPI_Init(&hspi2) != HAL_OK)
  {
    Error_Handler();
  }

}

void MX_SPI3_Init(void)
{

  /* SPI3 parameter configuration*/
  hspi3.Instance = SPI3;
  hspi3.Init.Mode = SPI_MODE_MASTER;
  hspi3.Init.Direction = SPI_DIRECTION_2LINES;
  hspi3.Init.DataSize = SPI_DATASIZE_8BIT;
  hspi3.Init.CLKPolarity = SPI_POLARITY_HIGH;
  hspi3.Init.CLKPhase = SPI_PHASE_2EDGE;
  hspi3.Init.NSS = SPI_NSS_SOFT;
  hspi3.Init.BaudRatePrescaler = SPI_BAUDRATEPRESCALER_4;
  hspi3.Init.FirstBit = SPI_FIRSTBIT_MSB;
  hspi3.Init.TIMode = SPI_TIMODE_DISABLE;
  hspi3.Init.CRCCalculation = SPI_CRCCALCULATION_DISABLE;
  hspi3.Init.CRCPolynomial = 0x0;
  hspi3.Init.NSSPMode = SPI_NSS_PULSE_ENABLE;
  hspi3.Init.NSSPolarity = SPI_NSS_POLARITY_LOW;
  hspi3.Init.FifoThreshold = SPI_FIFO_THRESHOLD_01DATA;
  hspi3.Init.TxCRCInitializationPattern = SPI_CRC_INITIALIZATION_ALL_ZERO_PATTERN;
  hspi3.Init.RxCRCInitializationPattern = SPI_CRC_INITIALIZATION_ALL_ZERO_PATTERN;
  hspi3.Init.MasterSSIdleness = SPI_MASTER_SS_IDLENESS_00CYCLE;
  hspi3.Init.MasterInterDataIdleness = SPI_MASTER_INTERDATA_IDLENESS_00CYCLE;
  hspi3.Init.MasterReceiverAutoSusp = SPI_MASTER_RX_AUTOSUSP_DISABLE;
  hspi3.Init.MasterKeepIOState = SPI_MASTER_KEEP_IO_STATE_ENABLE;
  hspi3.Init.IOSwap = SPI_IO_SWAP_DISABLE;
  if (HAL_SPI_Init(&hspi3) != HAL_OK)
  {
    Error_Handler();
  }

}

void MX_SPI4_Init(void)
{

  /* SPI4 parameter configuration*/
  hspi4.Instance = SPI4;
  hspi4.Init.Mode = SPI_MODE_MASTER;
  hspi4.Init.Direction = SPI_DIRECTION_2LINES;
  hspi4.Init.DataSize = SPI_DATASIZE_8BIT;
  hspi4.Init.CLKPolarity = SPI_POLARITY_HIGH;
  hspi4.Init.CLKPhase = SPI_PHASE_2EDGE;
  hspi4.Init.NSS = SPI_NSS_SOFT;
  hspi4.Init.BaudRatePrescaler = SPI_BAUDRATEPRESCALER_16;
  hspi4.Init.FirstBit = SPI_FIRSTBIT_MSB;
  hspi4.Init.TIMode = SPI_TIMODE_DISABLE;
  hspi4.Init.CRCCalculation = SPI_CRCCALCULATION_DISABLE;
  hspi4.Init.CRCPolynomial = 0x0;
  hspi4.Init.NSSPMode = SPI_NSS_PULSE_ENABLE;
  hspi4.Init.NSSPolarity = SPI_NSS_POLARITY_LOW;
  hspi4.Init.FifoThreshold = SPI_FIFO_THRESHOLD_01DATA;
  hspi4.Init.TxCRCInitializationPattern = SPI_CRC_INITIALIZATION_ALL_ZERO_PATTERN;
  hspi4.Init.RxCRCInitializationPattern = SPI_CRC_INITIALIZATION_ALL_ZERO_PATTERN;
  hspi4.Init.MasterSSIdleness = SPI_MASTER_SS_IDLENESS_00CYCLE;
  hspi4.Init.MasterInterDataIdleness = SPI_MASTER_INTERDATA_IDLENESS_01CYCLE;
  hspi4.Init.MasterReceiverAutoSusp = SPI_MASTER_RX_AUTOSUSP_DISABLE;
  hspi4.Init.MasterKeepIOState = SPI_MASTER_KEEP_IO_STATE_ENABLE;
  hspi4.Init.IOSwap = SPI_IO_SWAP_DISABLE;
  if (HAL_SPI_Init(&hspi4) != HAL_OK)
  {
    Error_Handler();
  }

}

void MX_TIM1_Init(void)
{

  TIM_MasterConfigTypeDef sMasterConfig = {0};
  TIM_OC_InitTypeDef sConfigOC = {0};
  TIM_BreakDeadTimeConfigTypeDef sBreakDeadTimeConfig = {0};

  htim1.Instance = TIM1;
  htim1.Init.Prescaler = (199);
  htim1.Init.CounterMode = TIM_COUNTERMODE_UP;
  htim1.Init.Period = (20000);
  htim1.Init.ClockDivision = TIM_CLOCKDIVISION_DIV1;
  htim1.Init.RepetitionCounter = 0;
  htim1.Init.AutoReloadPreload = TIM_AUTORELOAD_PRELOAD_ENABLE;
  if (HAL_TIM_PWM_Init(&htim1) != HAL_OK)
  {
    Error_Handler();
  }
  sMasterConfig.MasterOutputTrigger = TIM_TRGO_RESET;
  sMasterConfig.MasterOutputTrigger2 = TIM_TRGO2_RESET;
  sMasterConfig.MasterSlaveMode = TIM_MASTERSLAVEMODE_DISABLE;
  if (HAL_TIMEx_MasterConfigSynchronization(&htim1, &sMasterConfig) != HAL_OK)
  {
    Error_Handler();
  }
  sConfigOC.OCMode = TIM_OCMODE_PWM1;
  sConfigOC.Pulse = (1500);
  sConfigOC.OCPolarity = TIM_OCPOLARITY_HIGH;
  sConfigOC.OCNPolarity = TIM_OCNPOLARITY_HIGH;
  sConfigOC.OCFastMode = TIM_OCFAST_DISABLE;
  sConfigOC.OCIdleState = TIM_OCIDLESTATE_RESET;
  sConfigOC.OCNIdleState = TIM_OCNIDLESTATE_RESET;
  if (HAL_TIM_PWM_ConfigChannel(&htim1, &sConfigOC, TIM_CHANNEL_1) != HAL_OK)
  {
    Error_Handler();
  }
  if (HAL_TIM_PWM_ConfigChannel(&htim1, &sConfigOC, TIM_CHANNEL_2) != HAL_OK)
  {
    Error_Handler();
  }
  if (HAL_TIM_PWM_ConfigChannel(&htim1, &sConfigOC, TIM_CHANNEL_3) != HAL_OK)
  {
    Error_Handler();
  }
  if (HAL_TIM_PWM_ConfigChannel(&htim1, &sConfigOC, TIM_CHANNEL_4) != HAL_OK)
  {
    Error_Handler();
  }
  sBreakDeadTimeConfig.OffStateRunMode = TIM_OSSR_DISABLE;
  sBreakDeadTimeConfig.OffStateIDLEMode = TIM_OSSI_DISABLE;
  sBreakDeadTimeConfig.LockLevel = TIM_LOCKLEVEL_OFF;
  sBreakDeadTimeConfig.DeadTime = 0;
  sBreakDeadTimeConfig.BreakState = TIM_BREAK_DISABLE;
  sBreakDeadTimeConfig.BreakPolarity = TIM_BREAKPOLARITY_HIGH;
  sBreakDeadTimeConfig.BreakFilter = 0;
  sBreakDeadTimeConfig.Break2State = TIM_BREAK2_DISABLE;
  sBreakDeadTimeConfig.Break2Polarity = TIM_BREAK2POLARITY_HIGH;
  sBreakDeadTimeConfig.Break2Filter = 0;
  sBreakDeadTimeConfig.AutomaticOutput = TIM_AUTOMATICOUTPUT_DISABLE;
  if (HAL_TIMEx_ConfigBreakDeadTime(&htim1, &sBreakDeadTimeConfig) != HAL_OK)
  {
    Error_Handler();
  }
  HAL_TIM_MspPostInit(&htim1);

}

void MX_TIM3_Init(void)
{

  TIM_MasterConfigTypeDef sMasterConfig = {0};
  TIM_OC_InitTypeDef sConfigOC = {0};

  htim3.Instance = TIM3;
  htim3.Init.Prescaler = (199);
  htim3.Init.CounterMode = TIM_COUNTERMODE_UP;
  htim3.Init.Period = (20000);
  htim3.Init.ClockDivision = TIM_CLOCKDIVISION_DIV1;
  htim3.Init.AutoReloadPreload = TIM_AUTORELOAD_PRELOAD_ENABLE;
  if (HAL_TIM_PWM_Init(&htim3) != HAL_OK)
  {
    Error_Handler();
  }
  sMasterConfig.MasterOutputTrigger = TIM_TRGO_RESET;
  sMasterConfig.MasterSlaveMode = TIM_MASTERSLAVEMODE_DISABLE;
  if (HAL_TIMEx_MasterConfigSynchronization(&htim3, &sMasterConfig) != HAL_OK)
  {
    Error_Handler();
  }
  sConfigOC.OCMode = TIM_OCMODE_PWM1;
  sConfigOC.Pulse = (1500);
  sConfigOC.OCPolarity = TIM_OCPOLARITY_HIGH;
  sConfigOC.OCFastMode = TIM_OCFAST_DISABLE;
  if (HAL_TIM_PWM_ConfigChannel(&htim3, &sConfigOC, TIM_CHANNEL_1) != HAL_OK)
  {
    Error_Handler();
  }
  if (HAL_TIM_PWM_ConfigChannel(&htim3, &sConfigOC, TIM_CHANNEL_2) != HAL_OK)
  {
    Error_Handler();
  }
  HAL_TIM_MspPostInit(&htim3);

}

void MX_TIM4_Init(void)
{

  TIM_MasterConfigTypeDef sMasterConfig = {0};
  TIM_OC_InitTypeDef sConfigOC = {0};

  htim4.Instance = TIM4;
  htim4.Init.Prescaler = (199);
  htim4.Init.CounterMode = TIM_COUNTERMODE_UP;
  htim4.Init.Period = (20000);
  htim4.Init.ClockDivision = TIM_CLOCKDIVISION_DIV1;
  htim4.Init.AutoReloadPreload = TIM_AUTORELOAD_PRELOAD_ENABLE;
  if (HAL_TIM_PWM_Init(&htim4) != HAL_OK)
  {
    Error_Handler();
  }
  sMasterConfig.MasterOutputTrigger = TIM_TRGO_RESET;
  sMasterConfig.MasterSlaveMode = TIM_MASTERSLAVEMODE_DISABLE;
  if (HAL_TIMEx_MasterConfigSynchronization(&htim4, &sMasterConfig) != HAL_OK)
  {
    Error_Handler();
  }
  sConfigOC.OCMode = TIM_OCMODE_PWM1;
  sConfigOC.Pulse = (1500);
  sConfigOC.OCPolarity = TIM_OCPOLARITY_HIGH;
  sConfigOC.OCFastMode = TIM_OCFAST_DISABLE;
  if (HAL_TIM_PWM_ConfigChannel(&htim4, &sConfigOC, TIM_CHANNEL_1) != HAL_OK)
  {
    Error_Handler();
  }
  if (HAL_TIM_PWM_ConfigChannel(&htim4, &sConfigOC, TIM_CHANNEL_2) != HAL_OK)
  {
    Error_Handler();
  }
  if (HAL_TIM_PWM_ConfigChannel(&htim4, &sConfigOC, TIM_CHANNEL_3) != HAL_OK)
  {
    Error_Handler();
  }
  if (HAL_TIM_PWM_ConfigChannel(&htim4, &sConfigOC, TIM_CHANNEL_4) != HAL_OK)
  {
    Error_Handler();
  }
  HAL_TIM_MspPostInit(&htim4);

}

void MX_TIM5_Init(void)
{

  TIM_ClockConfigTypeDef sClockSourceConfig = {0};
  TIM_MasterConfigTypeDef sMasterConfig = {0};

  htim5.Instance = TIM5;
  htim5.Init.Prescaler = 199;
  htim5.Init.CounterMode = TIM_COUNTERMODE_UP;
  htim5.Init.Period = 0xffffffff;
  htim5.Init.ClockDivision = TIM_CLOCKDIVISION_DIV1;
  htim5.Init.AutoReloadPreload = TIM_AUTORELOAD_PRELOAD_DISABLE;
  if (HAL_TIM_Base_Init(&htim5) != HAL_OK)
  {
    Error_Handler();
  }
  sClockSourceConfig.ClockSource = TIM_CLOCKSOURCE_INTERNAL;
  if (HAL_TIM_ConfigClockSource(&htim5, &sClockSourceConfig) != HAL_OK)
  {
    Error_Handler();
  }
  sMasterConfig.MasterOutputTrigger = TIM_TRGO_UPDATE;
  sMasterConfig.MasterSlaveMode = TIM_MASTERSLAVEMODE_DISABLE;
  if (HAL_TIMEx_MasterConfigSynchronization(&htim5, &sMasterConfig) != HAL_OK)
  {
    Error_Handler();
  }

}

void MX_TIM7_Init(void)
{

  /* USER CODE BEGIN TIM7_Init 0 */
#define POLLING_PERIOD_US         (100) // 100us, 10kHz
//#define POLLING_FREQ_HZ          	(1000000/POLLING_PERIOD_US) // 10000 Hz
  /* USER CODE END TIM7_Init 0 */

  TIM_MasterConfigTypeDef sMasterConfig = {0};

  htim7.Instance = TIM7;
  htim7.Init.Prescaler = 199;
  htim7.Init.CounterMode = TIM_COUNTERMODE_UP;
  htim7.Init.Period = (POLLING_PERIOD_US);
  htim7.Init.AutoReloadPreload = TIM_AUTORELOAD_PRELOAD_ENABLE;
  if (HAL_TIM_Base_Init(&htim7) != HAL_OK)
  {
    Error_Handler();
  }
  sMasterConfig.MasterOutputTrigger = TIM_TRGO_RESET;
  sMasterConfig.MasterSlaveMode = TIM_MASTERSLAVEMODE_DISABLE;
  if (HAL_TIMEx_MasterConfigSynchronization(&htim7, &sMasterConfig) != HAL_OK)
  {
    Error_Handler();
  }

}

void MX_TIM8_Init(void)
{

  TIM_SlaveConfigTypeDef sSlaveConfig = {0};
  TIM_MasterConfigTypeDef sMasterConfig = {0};

  htim8.Instance = TIM8;
  htim8.Init.Prescaler = 0;
  htim8.Init.CounterMode = TIM_COUNTERMODE_UP;
  htim8.Init.Period = 65535;
  htim8.Init.ClockDivision = TIM_CLOCKDIVISION_DIV1;
  htim8.Init.RepetitionCounter = 0;
  htim8.Init.AutoReloadPreload = TIM_AUTORELOAD_PRELOAD_DISABLE;
  if (HAL_TIM_Base_Init(&htim8) != HAL_OK)
  {
    Error_Handler();
  }
  sSlaveConfig.SlaveMode = TIM_SLAVEMODE_EXTERNAL1;
  sSlaveConfig.InputTrigger = TIM_TS_ITR3;
  if (HAL_TIM_SlaveConfigSynchro(&htim8, &sSlaveConfig) != HAL_OK)
  {
    Error_Handler();
  }
  sMasterConfig.MasterOutputTrigger = TIM_TRGO_RESET;
  sMasterConfig.MasterOutputTrigger2 = TIM_TRGO2_RESET;
  sMasterConfig.MasterSlaveMode = TIM_MASTERSLAVEMODE_DISABLE;
  if (HAL_TIMEx_MasterConfigSynchronization(&htim8, &sMasterConfig) != HAL_OK)
  {
    Error_Handler();
  }

}

void MX_TIM12_Init(void)
{

  /* USER CODE BEGIN TIM12_Init 0 */
  #define ADIS165XX_TIM_PERIOD_US (500)
  /* USER CODE END TIM12_Init 0 */

  TIM_MasterConfigTypeDef sMasterConfig = {0};
  TIM_OC_InitTypeDef sConfigOC = {0};

  htim12.Instance = TIM12;
  htim12.Init.Prescaler = 199;
  htim12.Init.CounterMode = TIM_COUNTERMODE_UP;
  htim12.Init.Period = (ADIS165XX_TIM_PERIOD_US);
  htim12.Init.ClockDivision = TIM_CLOCKDIVISION_DIV1;
  htim12.Init.AutoReloadPreload = TIM_AUTORELOAD_PRELOAD_ENABLE;
  if (HAL_TIM_PWM_Init(&htim12) != HAL_OK)
  {
    Error_Handler();
  }
  sMasterConfig.MasterOutputTrigger = TIM_TRGO_RESET;
  sMasterConfig.MasterSlaveMode = TIM_MASTERSLAVEMODE_DISABLE;
  if (HAL_TIMEx_MasterConfigSynchronization(&htim12, &sMasterConfig) != HAL_OK)
  {
    Error_Handler();
  }
  sConfigOC.OCMode = TIM_OCMODE_PWM1;
  sConfigOC.Pulse = 250;
  sConfigOC.OCPolarity = TIM_OCPOLARITY_HIGH;
  sConfigOC.OCFastMode = TIM_OCFAST_DISABLE;
  if (HAL_TIM_PWM_ConfigChannel(&htim12, &sConfigOC, TIM_CHANNEL_1) != HAL_OK)
  {
    Error_Handler();
  }
  HAL_TIM_MspPostInit(&htim12);

}

void MX_TIM17_Init(void)
{

  htim17.Instance = TIM17;
  htim17.Init.Prescaler = 199;
  htim17.Init.CounterMode = TIM_COUNTERMODE_UP;
  htim17.Init.Period = 299;
  htim17.Init.ClockDivision = TIM_CLOCKDIVISION_DIV1;
  htim17.Init.RepetitionCounter = 0;
  htim17.Init.AutoReloadPreload = TIM_AUTORELOAD_PRELOAD_DISABLE;
  if (HAL_TIM_Base_Init(&htim17) != HAL_OK)
  {
    Error_Handler();
  }

}

void MX_USART1_UART_Init(void)
{

  huart1.Instance = USART1;
  huart1.Init.BaudRate = 115200;
  huart1.Init.WordLength = UART_WORDLENGTH_8B;
  huart1.Init.StopBits = UART_STOPBITS_1;
  huart1.Init.Parity = UART_PARITY_NONE;
  huart1.Init.Mode = UART_MODE_TX_RX;
  huart1.Init.HwFlowCtl = UART_HWCONTROL_NONE;
  huart1.Init.OverSampling = UART_OVERSAMPLING_16;
  huart1.Init.OneBitSampling = UART_ONE_BIT_SAMPLE_DISABLE;
  huart1.Init.ClockPrescaler = UART_PRESCALER_DIV1;
  huart1.AdvancedInit.AdvFeatureInit = UART_ADVFEATURE_NO_INIT;
  if (HAL_UART_Init(&huart1) != HAL_OK)
  {
    Error_Handler();
  }
  if (HAL_UARTEx_SetTxFifoThreshold(&huart1, UART_TXFIFO_THRESHOLD_1_8) != HAL_OK)
  {
    Error_Handler();
  }
  if (HAL_UARTEx_SetRxFifoThreshold(&huart1, UART_RXFIFO_THRESHOLD_1_8) != HAL_OK)
  {
    Error_Handler();
  }
  if (HAL_UARTEx_DisableFifoMode(&huart1) != HAL_OK)
  {
    Error_Handler();
  }

}

void MX_USART2_UART_Init(void)
{

  /* USER CODE BEGIN USART2_Init 0 */
#define UART2_BAUD        				(921600)
  /* USER CODE END USART2_Init 0 */

  huart2.Instance = USART2;
  huart2.Init.BaudRate = (UART2_BAUD);
  huart2.Init.WordLength = UART_WORDLENGTH_8B;
  huart2.Init.StopBits = UART_STOPBITS_1;
  huart2.Init.Parity = UART_PARITY_NONE;
  huart2.Init.Mode = UART_MODE_TX_RX;
  huart2.Init.HwFlowCtl = UART_HWCONTROL_NONE;
  huart2.Init.OverSampling = UART_OVERSAMPLING_16;
  huart2.Init.OneBitSampling = UART_ONE_BIT_SAMPLE_DISABLE;
  huart2.Init.ClockPrescaler = UART_PRESCALER_DIV1;
  huart2.AdvancedInit.AdvFeatureInit = UART_ADVFEATURE_NO_INIT;
  if (HAL_UART_Init(&huart2) != HAL_OK)
  {
    Error_Handler();
  }
  if (HAL_UARTEx_SetTxFifoThreshold(&huart2, UART_TXFIFO_THRESHOLD_1_8) != HAL_OK)
  {
    Error_Handler();
  }
  if (HAL_UARTEx_SetRxFifoThreshold(&huart2, UART_RXFIFO_THRESHOLD_1_8) != HAL_OK)
  {
    Error_Handler();
  }
  if (HAL_UARTEx_DisableFifoMode(&huart2) != HAL_OK)
  {
    Error_Handler();
  }

}

void MX_USART3_UART_Init(void)
{

  huart3.Instance = USART3;
  huart3.Init.BaudRate = 100000;
  huart3.Init.WordLength = UART_WORDLENGTH_9B;
  huart3.Init.StopBits = UART_STOPBITS_2;
  huart3.Init.Parity = UART_PARITY_EVEN;
  huart3.Init.Mode = UART_MODE_TX_RX;
  huart3.Init.HwFlowCtl = UART_HWCONTROL_NONE;
  huart3.Init.OverSampling = UART_OVERSAMPLING_16;
  huart3.Init.OneBitSampling = UART_ONE_BIT_SAMPLE_DISABLE;
  huart3.Init.ClockPrescaler = UART_PRESCALER_DIV1;
  huart3.AdvancedInit.AdvFeatureInit = UART_ADVFEATURE_TXINVERT_INIT|UART_ADVFEATURE_RXINVERT_INIT;
  huart3.AdvancedInit.TxPinLevelInvert = UART_ADVFEATURE_TXINV_ENABLE;
  huart3.AdvancedInit.RxPinLevelInvert = UART_ADVFEATURE_RXINV_ENABLE;
  if (HAL_UART_Init(&huart3) != HAL_OK)
  {
    Error_Handler();
  }
  if (HAL_UARTEx_SetTxFifoThreshold(&huart3, UART_TXFIFO_THRESHOLD_1_8) != HAL_OK)
  {
    Error_Handler();
  }
  if (HAL_UARTEx_SetRxFifoThreshold(&huart3, UART_RXFIFO_THRESHOLD_1_8) != HAL_OK)
  {
    Error_Handler();
  }
  if (HAL_UARTEx_DisableFifoMode(&huart3) != HAL_OK)
  {
    Error_Handler();
  }

}

void MX_USB_OTG_FS_PCD_Init(void)
{

  hpcd_USB_OTG_FS.Instance = USB_OTG_FS;
  hpcd_USB_OTG_FS.Init.dev_endpoints = 9;
  hpcd_USB_OTG_FS.Init.speed = PCD_SPEED_FULL;
  hpcd_USB_OTG_FS.Init.dma_enable = DISABLE;
  hpcd_USB_OTG_FS.Init.phy_itface = PCD_PHY_EMBEDDED;
  hpcd_USB_OTG_FS.Init.Sof_enable = DISABLE;
  hpcd_USB_OTG_FS.Init.low_power_enable = DISABLE;
  hpcd_USB_OTG_FS.Init.lpm_enable = DISABLE;
  hpcd_USB_OTG_FS.Init.battery_charging_enable = DISABLE;
  hpcd_USB_OTG_FS.Init.vbus_sensing_enable = DISABLE;
  hpcd_USB_OTG_FS.Init.use_dedicated_ep1 = DISABLE;
  if (HAL_PCD_Init(&hpcd_USB_OTG_FS) != HAL_OK)
  {
    Error_Handler();
  }

}

void MX_BDMA_Init(void)
{

  /* DMA controller clock enable */
  __HAL_RCC_BDMA_CLK_ENABLE();

  /* DMA interrupt init */
  /* BDMA_Channel0_IRQn interrupt configuration */
  HAL_NVIC_SetPriority(BDMA_Channel0_IRQn, 5, 0);
  HAL_NVIC_EnableIRQ(BDMA_Channel0_IRQn);

}

void MX_DMA_Init(void)
{

  /* DMA controller clock enable */
  __HAL_RCC_DMA1_CLK_ENABLE();
  __HAL_RCC_DMA2_CLK_ENABLE();

  /* DMA interrupt init */
  /* DMA1_Stream0_IRQn interrupt configuration */
  HAL_NVIC_SetPriority(DMA1_Stream0_IRQn, 5, 0);
  HAL_NVIC_EnableIRQ(DMA1_Stream0_IRQn);
  /* DMA1_Stream1_IRQn interrupt configuration */
  HAL_NVIC_SetPriority(DMA1_Stream1_IRQn, 5, 0);
  HAL_NVIC_EnableIRQ(DMA1_Stream1_IRQn);
  /* DMA1_Stream2_IRQn interrupt configuration */
  HAL_NVIC_SetPriority(DMA1_Stream2_IRQn, 5, 0);
  HAL_NVIC_EnableIRQ(DMA1_Stream2_IRQn);
  /* DMA1_Stream3_IRQn interrupt configuration */
  HAL_NVIC_SetPriority(DMA1_Stream3_IRQn, 5, 0);
  HAL_NVIC_EnableIRQ(DMA1_Stream3_IRQn);
  /* DMA1_Stream4_IRQn interrupt configuration */
  HAL_NVIC_SetPriority(DMA1_Stream4_IRQn, 5, 0);
  HAL_NVIC_EnableIRQ(DMA1_Stream4_IRQn);
  /* DMA1_Stream5_IRQn interrupt configuration */
  HAL_NVIC_SetPriority(DMA1_Stream5_IRQn, 5, 0);
  HAL_NVIC_EnableIRQ(DMA1_Stream5_IRQn);
  /* DMA1_Stream6_IRQn interrupt configuration */
  HAL_NVIC_SetPriority(DMA1_Stream6_IRQn, 5, 0);
  HAL_NVIC_EnableIRQ(DMA1_Stream6_IRQn);
  /* DMA1_Stream7_IRQn interrupt configuration */
  HAL_NVIC_SetPriority(DMA1_Stream7_IRQn, 5, 0);
  HAL_NVIC_EnableIRQ(DMA1_Stream7_IRQn);
  /* DMA2_Stream0_IRQn interrupt configuration */
  HAL_NVIC_SetPriority(DMA2_Stream0_IRQn, 5, 0);
  HAL_NVIC_EnableIRQ(DMA2_Stream0_IRQn);
  /* DMA2_Stream1_IRQn interrupt configuration */
  HAL_NVIC_SetPriority(DMA2_Stream1_IRQn, 5, 0);
  HAL_NVIC_EnableIRQ(DMA2_Stream1_IRQn);
  /* DMA2_Stream2_IRQn interrupt configuration */
  HAL_NVIC_SetPriority(DMA2_Stream2_IRQn, 5, 0);
  HAL_NVIC_EnableIRQ(DMA2_Stream2_IRQn);
  /* DMA2_Stream3_IRQn interrupt configuration */
  HAL_NVIC_SetPriority(DMA2_Stream3_IRQn, 5, 0);
  HAL_NVIC_EnableIRQ(DMA2_Stream3_IRQn);
  /* DMA2_Stream4_IRQn interrupt configuration */
  HAL_NVIC_SetPriority(DMA2_Stream4_IRQn, 5, 0);
  HAL_NVIC_EnableIRQ(DMA2_Stream4_IRQn);
  /* DMA2_Stream5_IRQn interrupt configuration */
  HAL_NVIC_SetPriority(DMA2_Stream5_IRQn, 5, 0);
  HAL_NVIC_EnableIRQ(DMA2_Stream5_IRQn);
  /* DMA2_Stream6_IRQn interrupt configuration */
  HAL_NVIC_SetPriority(DMA2_Stream6_IRQn, 5, 0);
  HAL_NVIC_EnableIRQ(DMA2_Stream6_IRQn);
  /* DMA2_Stream7_IRQn interrupt configuration */
  HAL_NVIC_SetPriority(DMA2_Stream7_IRQn, 5, 0);
  HAL_NVIC_EnableIRQ(DMA2_Stream7_IRQn);

}

void MX_GPIO_Init(void)
{
  GPIO_InitTypeDef GPIO_InitStruct = {0};

  /* GPIO Ports Clock Enable */
  __HAL_RCC_GPIOC_CLK_ENABLE();
  __HAL_RCC_GPIOE_CLK_ENABLE();
  __HAL_RCC_GPIOB_CLK_ENABLE();
  __HAL_RCC_GPIOA_CLK_ENABLE();
  __HAL_RCC_GPIOD_CLK_ENABLE();
  __HAL_RCC_GPIOH_CLK_ENABLE();

  /*Configure GPIO pin Output Level */
  HAL_GPIO_WritePin(GPIOC, TP4_Pin|TP6_Pin, GPIO_PIN_RESET);

  /*Configure GPIO pin Output Level */
  HAL_GPIO_WritePin(GPIOE, J105_2_SPI4_EXT_CS_Pin|DPS310_CSn_Pin, GPIO_PIN_SET);

  /*Configure GPIO pin Output Level */
  HAL_GPIO_WritePin(GPIOE, ADIS165XX_CSn_Pin|J000_JETSON_DRDY_Pin|LED_RED_Pin|LED_GRN_Pin
                          |LED_BLU_Pin|ADIS165XX_RESET_Pin, GPIO_PIN_RESET);

  /*Configure GPIO pin Output Level */
  HAL_GPIO_WritePin(BMI088_ACCEL_CSn_GPIO_Port, BMI088_ACCEL_CSn_Pin, GPIO_PIN_SET);

  /*Configure GPIO pin Output Level */
  HAL_GPIO_WritePin(GPIOB, J105_2_SPI4_EXT_CLK_Pin|TP5_Pin|J105_3_SYNC_OUT_Pin, GPIO_PIN_RESET);

  /*Configure GPIO pin Output Level */
  HAL_GPIO_WritePin(BMI088_GYRO_CSn_GPIO_Port, BMI088_GYRO_CSn_Pin, GPIO_PIN_SET);

  /*Configure GPIO pin Output Level */
  HAL_GPIO_WritePin(IIS2MDC_CSn_GPIO_Port, IIS2MDC_CSn_Pin, GPIO_PIN_SET);

  /*Configure GPIO pin : J000_JETSON_SYNC_Pin */
  GPIO_InitStruct.Pin = J000_JETSON_SYNC_Pin;
  GPIO_InitStruct.Mode = GPIO_MODE_IT_RISING;
  GPIO_InitStruct.Pull = GPIO_PULLDOWN;
  HAL_GPIO_Init(J000_JETSON_SYNC_GPIO_Port, &GPIO_InitStruct);

  /*Configure GPIO pins : BMI088_ACCEL_DRDY_Pin BMI088_GYRO_DRDY_Pin J105_3_SYNC_IN_Pin GPS_1PPS_Pin */
  GPIO_InitStruct.Pin = BMI088_ACCEL_DRDY_Pin|BMI088_GYRO_DRDY_Pin|J105_3_SYNC_IN_Pin|GPS_1PPS_Pin;
  GPIO_InitStruct.Mode = GPIO_MODE_IT_RISING;
  GPIO_InitStruct.Pull = GPIO_PULLDOWN;
  HAL_GPIO_Init(GPIOA, &GPIO_InitStruct);

  /*Configure GPIO pins : TP4_Pin TP6_Pin */
  GPIO_InitStruct.Pin = TP4_Pin|TP6_Pin;
  GPIO_InitStruct.Mode = GPIO_MODE_OUTPUT_PP;
  GPIO_InitStruct.Pull = GPIO_NOPULL;
  GPIO_InitStruct.Speed = GPIO_SPEED_FREQ_LOW;
  HAL_GPIO_Init(GPIOC, &GPIO_InitStruct);

  /*Configure GPIO pins : J105_2_SPI4_EXT_CS_Pin ADIS165XX_CSn_Pin DPS310_CSn_Pin J000_JETSON_DRDY_Pin
                           LED_RED_Pin LED_GRN_Pin LED_BLU_Pin */
  GPIO_InitStruct.Pin = J105_2_SPI4_EXT_CS_Pin|ADIS165XX_CSn_Pin|DPS310_CSn_Pin|J000_JETSON_DRDY_Pin
                          |LED_RED_Pin|LED_GRN_Pin|LED_BLU_Pin;
  GPIO_InitStruct.Mode = GPIO_MODE_OUTPUT_PP;
  GPIO_InitStruct.Pull = GPIO_NOPULL;
  GPIO_InitStruct.Speed = GPIO_SPEED_FREQ_LOW;
  HAL_GPIO_Init(GPIOE, &GPIO_InitStruct);

  /*Configure GPIO pin : ADIS165XX_DRDY_Pin */
  GPIO_InitStruct.Pin = ADIS165XX_DRDY_Pin;
  GPIO_InitStruct.Mode = GPIO_MODE_IT_RISING;
  GPIO_InitStruct.Pull = GPIO_PULLDOWN;
  HAL_GPIO_Init(ADIS165XX_DRDY_GPIO_Port, &GPIO_InitStruct);

  /*Configure GPIO pin : J105_2_SPI4_EXT_RST_Pin */
  GPIO_InitStruct.Pin = J105_2_SPI4_EXT_RST_Pin;
  GPIO_InitStruct.Mode = GPIO_MODE_INPUT;
  GPIO_InitStruct.Pull = GPIO_NOPULL;
  HAL_GPIO_Init(J105_2_SPI4_EXT_RST_GPIO_Port, &GPIO_InitStruct);

  /*Configure GPIO pins : IIS2MDC_DRDY_Pin J105_2_DRDY_Pin PITOT_DRDY_Pin */
  GPIO_InitStruct.Pin = IIS2MDC_DRDY_Pin|J105_2_DRDY_Pin|PITOT_DRDY_Pin;
  GPIO_InitStruct.Mode = GPIO_MODE_IT_RISING;
  GPIO_InitStruct.Pull = GPIO_PULLDOWN;
  HAL_GPIO_Init(GPIOE, &GPIO_InitStruct);

  /*Configure GPIO pin : BMI088_ACCEL_CSn_Pin */
  GPIO_InitStruct.Pin = BMI088_ACCEL_CSn_Pin;
  GPIO_InitStruct.Mode = GPIO_MODE_OUTPUT_PP;
  GPIO_InitStruct.Pull = GPIO_NOPULL;
  GPIO_InitStruct.Speed = GPIO_SPEED_FREQ_LOW;
  HAL_GPIO_Init(BMI088_ACCEL_CSn_GPIO_Port, &GPIO_InitStruct);

  /*Configure GPIO pin : DPS310_DRDY_Pin */
  GPIO_InitStruct.Pin = DPS310_DRDY_Pin;
  GPIO_InitStruct.Mode = GPIO_MODE_IT_RISING;
  GPIO_InitStruct.Pull = GPIO_PULLDOWN;
  HAL_GPIO_Init(DPS310_DRDY_GPIO_Port, &GPIO_InitStruct);

  /*Configure GPIO pins : J105_2_SPI4_EXT_CLK_Pin TP5_Pin J105_3_SYNC_OUT_Pin IIS2MDC_CSn_Pin */
  GPIO_InitStruct.Pin = J105_2_SPI4_EXT_CLK_Pin|TP5_Pin|J105_3_SYNC_OUT_Pin|IIS2MDC_CSn_Pin;
  GPIO_InitStruct.Mode = GPIO_MODE_OUTPUT_PP;
  GPIO_InitStruct.Pull = GPIO_NOPULL;
  GPIO_InitStruct.Speed = GPIO_SPEED_FREQ_LOW;
  HAL_GPIO_Init(GPIOB, &GPIO_InitStruct);

  /*Configure GPIO pin : BMI088_GYRO_CSn_Pin */
  GPIO_InitStruct.Pin = BMI088_GYRO_CSn_Pin;
  GPIO_InitStruct.Mode = GPIO_MODE_OUTPUT_PP;
  GPIO_InitStruct.Pull = GPIO_NOPULL;
  GPIO_InitStruct.Speed = GPIO_SPEED_FREQ_LOW;
  HAL_GPIO_Init(BMI088_GYRO_CSn_GPIO_Port, &GPIO_InitStruct);

  /*Configure GPIO pin : ADIS165XX_RESET_Pin */
  GPIO_InitStruct.Pin = ADIS165XX_RESET_Pin;
  GPIO_InitStruct.Mode = GPIO_MODE_OUTPUT_PP;
  GPIO_InitStruct.Pull = GPIO_PULLDOWN;
  GPIO_InitStruct.Speed = GPIO_SPEED_FREQ_LOW;
  HAL_GPIO_Init(ADIS165XX_RESET_GPIO_Port, &GPIO_InitStruct);

  /* EXTI interrupt init*/
  HAL_NVIC_SetPriority(EXTI0_IRQn, 5, 0);
  HAL_NVIC_EnableIRQ(EXTI0_IRQn);

  HAL_NVIC_SetPriority(EXTI1_IRQn, 5, 0);
  HAL_NVIC_EnableIRQ(EXTI1_IRQn);

  HAL_NVIC_SetPriority(EXTI2_IRQn, 5, 0);
  HAL_NVIC_EnableIRQ(EXTI2_IRQn);

  HAL_NVIC_SetPriority(EXTI3_IRQn, 5, 0);
  HAL_NVIC_EnableIRQ(EXTI3_IRQn);

  HAL_NVIC_SetPriority(EXTI9_5_IRQn, 5, 0);
  HAL_NVIC_EnableIRQ(EXTI9_5_IRQn);

  HAL_NVIC_SetPriority(EXTI15_10_IRQn, 5, 0);
  HAL_NVIC_EnableIRQ(EXTI15_10_IRQn);

/* USER CODE BEGIN MX_GPIO_Init_2 */
	HAL_NVIC_DisableIRQ(EXTI0_IRQn);
	HAL_NVIC_DisableIRQ(EXTI1_IRQn);
	HAL_NVIC_DisableIRQ(EXTI2_IRQn);
	HAL_NVIC_DisableIRQ(EXTI3_IRQn);
	HAL_NVIC_DisableIRQ(EXTI9_5_IRQn);
	HAL_NVIC_DisableIRQ(EXTI15_10_IRQn);
/* USER CODE END MX_GPIO_Init_2 */
}

/* MPU Configuration */

void MPU_Config(void)
{
  MPU_Region_InitTypeDef MPU_InitStruct = {0};

  /* Disables the MPU */
  HAL_MPU_Disable();

  /** Initializes and configures the Region and the memory to be protected
  */
  MPU_InitStruct.Enable = MPU_REGION_ENABLE;
  MPU_InitStruct.Number = MPU_REGION_NUMBER0;
  MPU_InitStruct.BaseAddress = 0x30040000;
  MPU_InitStruct.Size = MPU_REGION_SIZE_32KB;
  MPU_InitStruct.SubRegionDisable = 0x00;
  MPU_InitStruct.TypeExtField = MPU_TEX_LEVEL0;
  MPU_InitStruct.AccessPermission = MPU_REGION_FULL_ACCESS;
  MPU_InitStruct.DisableExec = MPU_INSTRUCTION_ACCESS_ENABLE;
  MPU_InitStruct.IsShareable = MPU_ACCESS_SHAREABLE;
  MPU_InitStruct.IsCacheable = MPU_ACCESS_CACHEABLE;
  MPU_InitStruct.IsBufferable = MPU_ACCESS_NOT_BUFFERABLE;

  HAL_MPU_ConfigRegion(&MPU_InitStruct);

  /** Initializes and configures the Region and the memory to be protected
  */
  MPU_InitStruct.Number = MPU_REGION_NUMBER1;
  MPU_InitStruct.BaseAddress = 0x38000000;
  MPU_InitStruct.Size = MPU_REGION_SIZE_64KB;
  MPU_InitStruct.SubRegionDisable = 0x0;

  HAL_MPU_ConfigRegion(&MPU_InitStruct);
  /* Enables the MPU */
  HAL_MPU_Enable(MPU_PRIVILEGED_DEFAULT);

}

void Error_Handler(void)
{
  __disable_irq();
  while (1)
  {
  }
}
